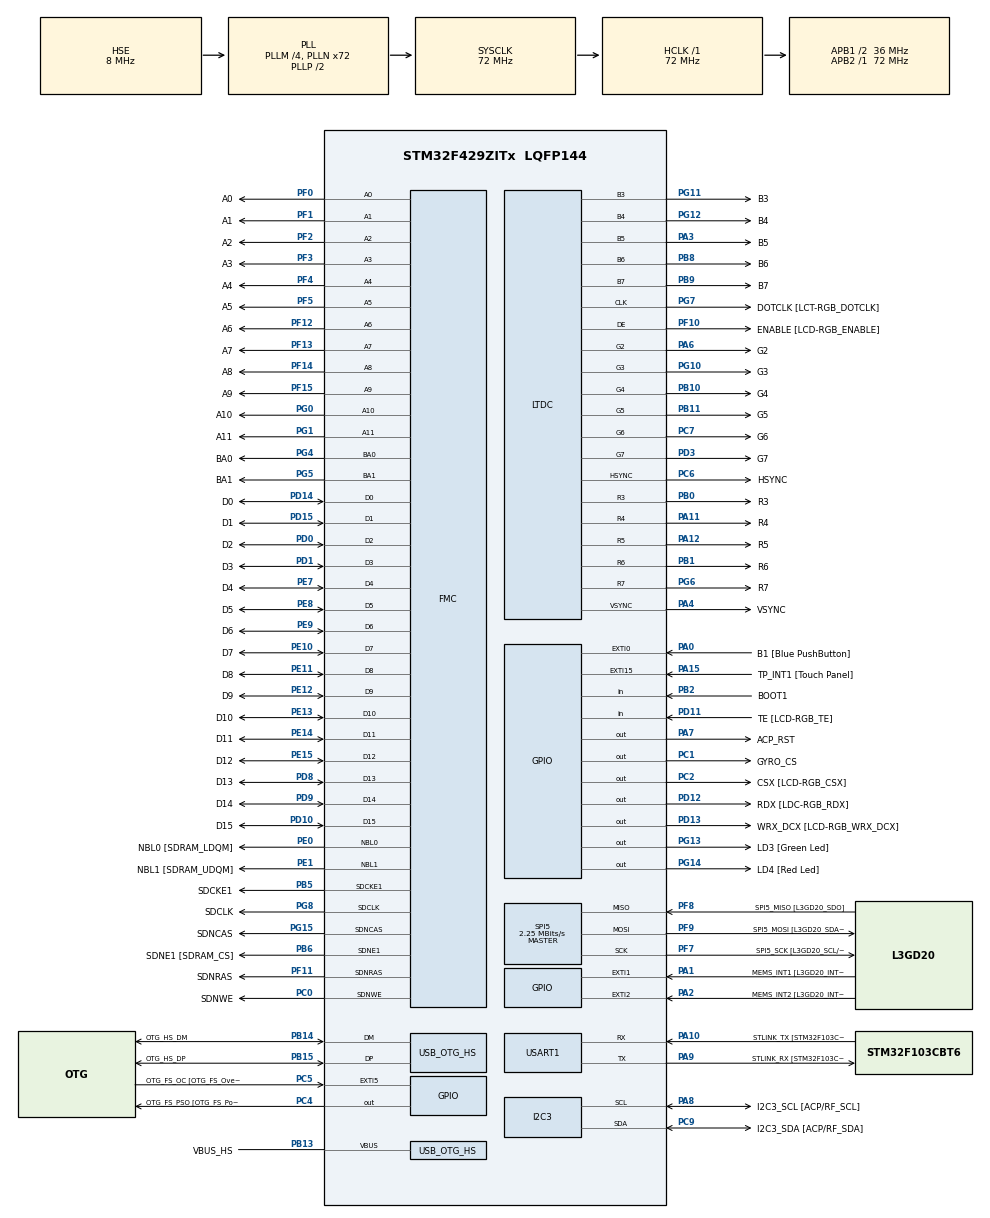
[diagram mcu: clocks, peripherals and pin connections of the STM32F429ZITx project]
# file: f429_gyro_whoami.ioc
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FMC.CASLatency1=FMC_SDRAM_CAS_LATENCY_3
FMC.ExitSelfRefreshDelay1=7
FMC.LoadToActiveDelay1=2
FMC.RCDDelay1=2
FMC.RPDelay1=2
FMC.RPDelay2=2
FMC.ReadBurst1=FMC_SDRAM_RBURST_DISABLE
FMC.ReadPipeDelay1=FMC_SDRAM_RPIPE_DELAY_1
FMC.ReadPipeDelay2=FMC_SDRAM_RPIPE_DELAY_1
FMC.RowCycleDelay1=7
FMC.RowCycleDelay2=7
FMC.SDClockPeriod1=FMC_SDRAM_CLOCK_PERIOD_2
FMC.SDClockPeriod2=FMC_SDRAM_CLOCK_PERIOD_2
FMC.SelfRefreshTime1=4
FMC.WriteRecoveryTime1=3
FREERTOS.Tasks01=defaultTask,0,4096,StartDefaultTask,Default,NULL,Dynamic,NULL,NULL
FREERTOS.configCHECK_FOR_STACK_OVERFLOW=2
FREERTOS.configTOTAL_HEAP_SIZE=32768
FREERTOS.configUSE_APPLICATION_TASK_TAG=1
FREERTOS.configUSE_COUNTING_SEMAPHORES=1
FREERTOS.configUSE_IDLE_HOOK=1
FREERTOS.configUSE_MALLOC_FAILED_HOOK=1
FREERTOS.configUSE_RECURSIVE_MUTEXES=1
LTDC.ActiveH=320
LTDC.ActiveW=240
LTDC.Alpha_L0=255
LTDC.BlendingFactor1_L0=LTDC_BLENDING_FACTOR1_PAxCA
LTDC.BlendingFactor2_L0=LTDC_BLENDING_FACTOR2_PAxCA
LTDC.FBStartAdress_L0=0xD0000000
LTDC.HBP=20
LTDC.HFP=10
LTDC.HSync=10
LTDC.ImageHeight_L0=320
LTDC.ImageWidth_L0=240
LTDC.Layers=0
LTDC.PixelFormat_L0=LTDC_PIXEL_FORMAT_RGB565
LTDC.VFP=4
LTDC.VSync=2
LTDC.WindowX1_L0=240
LTDC.WindowY1_L0=320
Mcu.Family=STM32F4
Mcu.Name=STM32F429ZITx
Mcu.Package=LQFP144
NVIC.DMA2D_IRQn=true\:5\:0\:true\:false\:true\:true\:true\:true\:true
NVIC.LTDC_IRQn=true\:5\:0\:true\:false\:true\:true\:true\:true\:true
NVIC.OTG_HS_IRQn=true\:5\:0\:false\:false\:true\:true\:true\:true\:true
NVIC.PriorityGroup=NVIC_PRIORITYGROUP_4
NVIC.TIM6_DAC_IRQn=true\:15\:0\:false\:false\:true\:false\:false\:true\:true
NVIC.TimeBase=TIM6_DAC_IRQn
NVIC.TimeBaseIP=TIM6
PA0/WKUP.GPIO_Label=B1 [Blue PushButton]
PA0/WKUP.GPIO_ModeDefaultEXTI=GPIO_MODE_EVT_RISING
PA0/WKUP.GPIO_PuPd=GPIO_NOPULL
PA0/WKUP.Signal=GPXTI0
PA1.GPIO_Label=MEMS_INT1 [L3GD20_INT1]
PA1.GPIO_ModeDefaultEXTI=GPIO_MODE_EVT_RISING
PA1.GPIO_PuPd=GPIO_NOPULL
PA1.Signal=GPXTI1
PA10.GPIO_Label=STLINK_TX [STM32F103CBT6_PA2]
PA10.Mode=Asynchronous
PA10.Signal=USART1_RX
PA11.GPIO_Label=R4
PA11.GPIO_Mode=GPIO_MODE_AF_PP
PA11.GPIO_PuPd=GPIO_NOPULL
PA11.GPIO_Speed=GPIO_SPEED_FREQ_LOW
PA11.Mode=RGB565
PA11.Signal=LTDC_R4
PA12.GPIO_Label=R5
PA12.GPIO_Mode=GPIO_MODE_AF_PP
PA12.GPIO_PuPd=GPIO_NOPULL
PA12.GPIO_Speed=GPIO_SPEED_FREQ_LOW
PA12.Mode=RGB565
PA12.Signal=LTDC_R5
PA13.GPIO_Label=SWDIO
PA13.Mode=Serial_Wire
PA13.Signal=SYS_JTMS-SWDIO
PA14.GPIO_Label=SWCLK
PA14.Mode=Serial_Wire
PA14.Signal=SYS_JTCK-SWCLK
PA15.GPIO_Label=TP_INT1 [Touch Panel]
PA15.GPIO_ModeDefaultEXTI=GPIO_MODE_EVT_RISING
PA15.GPIO_PuPd=GPIO_NOPULL
PA15.Signal=GPXTI15
PA2.GPIO_Label=MEMS_INT2 [L3GD20_INT2]
PA2.GPIO_ModeDefaultEXTI=GPIO_MODE_EVT_RISING
PA2.GPIO_PuPd=GPIO_NOPULL
PA2.Signal=GPXTI2
PA3.GPIO_Label=B5
PA3.GPIO_Mode=GPIO_MODE_AF_PP
PA3.GPIO_PuPd=GPIO_NOPULL
PA3.GPIO_Speed=GPIO_SPEED_FREQ_LOW
PA3.Mode=RGB565
PA3.Signal=LTDC_B5
PA4.GPIO_Label=VSYNC
PA4.GPIO_Mode=GPIO_MODE_AF_PP
PA4.GPIO_PuPd=GPIO_NOPULL
PA4.GPIO_Speed=GPIO_SPEED_FREQ_LOW
PA4.Mode=RGB565
PA4.Signal=LTDC_VSYNC
PA6.GPIO_Label=G2
PA6.GPIO_Mode=GPIO_MODE_AF_PP
PA6.GPIO_PuPd=GPIO_NOPULL
PA6.GPIO_Speed=GPIO_SPEED_FREQ_LOW
PA6.Mode=RGB565
PA6.Signal=LTDC_G2
PA7.GPIO_Label=ACP_RST
PA7.GPIO_Mode=GPIO_MODE_OUTPUT_PP
PA7.GPIO_PuPd=GPIO_NOPULL
PA7.GPIO_Speed=GPIO_SPEED_FREQ_LOW
PA7.Signal=GPIO_Output
PA8.GPIO_Label=I2C3_SCL [ACP/RF_SCL]
PA8.GPIO_Mode=GPIO_MODE_AF_OD
PA8.GPIO_Pu=GPIO_PULLUP
PA8.GPIO_PuPd=GPIO_NOPULL
PA8.GPIO_Speed=GPIO_SPEED_FREQ_LOW
PA8.Mode=I2C
PA8.Signal=I2C3_SCL
PA9.GPIO_Label=STLINK_RX [STM32F103CBT6_PA3]
PA9.Mode=Asynchronous
PA9.Signal=USART1_TX
PB0.GPIO_Label=R3
PB0.GPIO_Mode=GPIO_MODE_AF_PP
PB0.GPIO_PuPd=GPIO_NOPULL
PB0.GPIO_Speed=GPIO_SPEED_FREQ_LOW
PB0.Mode=RGB565
PB0.Signal=LTDC_R3
PB1.GPIO_Label=R6
PB1.GPIO_Mode=GPIO_MODE_AF_PP
PB1.GPIO_PuPd=GPIO_NOPULL
PB1.GPIO_Speed=GPIO_SPEED_FREQ_LOW
PB1.Mode=RGB565
PB1.Signal=LTDC_R6
PB10.GPIO_Label=G4
PB10.GPIO_Mode=GPIO_MODE_AF_PP
PB10.GPIO_PuPd=GPIO_NOPULL
PB10.GPIO_Speed=GPIO_SPEED_FREQ_LOW
PB10.Mode=RGB565
PB10.Signal=LTDC_G4
PB11.GPIO_Label=G5
PB11.GPIO_Mode=GPIO_MODE_AF_PP
PB11.GPIO_PuPd=GPIO_NOPULL
PB11.GPIO_Speed=GPIO_SPEED_FREQ_LOW
PB11.Mode=RGB565
PB11.Signal=LTDC_G5
PB12.GPIO_Label=OTG_HS_ID
PB12.GPIO_Mode=GPIO_MODE_AF_PP
PB12.GPIO_PuPd=GPIO_NOPULL
PB12.GPIO_Speed=GPIO_SPEED_FREQ_LOW
PB12.Signal=USB_OTG_HS_ID
PB13.GPIO_Label=VBUS_HS
PB13.GPIO_Mode=GPIO_MODE_INPUT
PB13.GPIO_PuPd=GPIO_NOPULL
PB13.Mode=Activate_VBUS_FS
PB13.Signal=USB_OTG_HS_VBUS
PB14.GPIO_Label=OTG_HS_DM
PB14.GPIO_Mode=GPIO_MODE_AF_PP
PB14.GPIO_PuPd=GPIO_NOPULL
PB14.GPIO_Speed=GPIO_SPEED_FREQ_LOW
PB14.Mode=Host_FS
PB14.Signal=USB_OTG_HS_DM
PB15.GPIO_Label=OTG_HS_DP
PB15.GPIO_Mode=GPIO_MODE_AF_PP
PB15.GPIO_PuPd=GPIO_NOPULL
PB15.GPIO_Speed=GPIO_SPEED_FREQ_LOW
PB15.Mode=Host_FS
PB15.Signal=USB_OTG_HS_DP
PB2/BOOT1.GPIO_Label=BOOT1
PB2/BOOT1.GPIO_Mode=GPIO_MODE_INPUT
PB2/BOOT1.GPIO_PuPd=GPIO_NOPULL
PB2/BOOT1.Signal=GPIO_Input
PB5.GPIO_Label=SDCKE1
PB5.GPIO_Mode=GPIO_MODE_AF_PP
PB5.GPIO_PuPd=GPIO_NOPULL
PB5.GPIO_Speed=GPIO_SPEED_FREQ_VERY_HIGH
PB5.Mode=SdramChipSelect2_1
PB5.Signal=FMC_SDCKE1
PB6.GPIO_Label=SDNE1 [SDRAM_CS]
PB6.GPIO_Mode=GPIO_MODE_AF_PP
PB6.GPIO_PuPd=GPIO_NOPULL
PB6.GPIO_Speed=GPIO_SPEED_FREQ_VERY_HIGH
PB6.Mode=SdramChipSelect2_1
PB6.Signal=FMC_SDNE1
PB8.GPIO_Label=B6
PB8.GPIO_Mode=GPIO_MODE_AF_PP
PB8.GPIO_PuPd=GPIO_NOPULL
PB8.GPIO_Speed=GPIO_SPEED_FREQ_LOW
PB8.Mode=RGB565
PB8.Signal=LTDC_B6
PB9.GPIO_Label=B7
PB9.GPIO_Mode=GPIO_MODE_AF_PP
PB9.GPIO_PuPd=GPIO_NOPULL
PB9.GPIO_Speed=GPIO_SPEED_FREQ_LOW
PB9.Mode=RGB565
PB9.Signal=LTDC_B7
PC0.GPIO_Label=SDNWE
PC0.GPIO_Mode=GPIO_MODE_AF_PP
PC0.GPIO_PuPd=GPIO_NOPULL
PC0.GPIO_Speed=GPIO_SPEED_FREQ_VERY_HIGH
PC0.Signal=FMC_SDNWE
PC1.GPIO_Label=GYRO_CS
PC1.GPIO_Mode=GPIO_MODE_OUTPUT_PP
PC1.GPIO_PuPd=GPIO_NOPULL
PC1.GPIO_Speed=GPIO_SPEED_FREQ_LOW
PC1.PinState=GPIO_PIN_SET
PC1.Signal=GPIO_Output
PC10.GPIO_Label=R2
PC10.GPIO_Mode=GPIO_MODE_AF_PP
PC10.GPIO_PuPd=GPIO_NOPULL
PC10.GPIO_Speed=GPIO_SPEED_FREQ_LOW
PC10.Signal=LTDC_R2
PC14/OSC32_IN.GPIO_Label=PC14-OSC32_IN
PC14/OSC32_IN.Signal=RCC_OSC32_IN
PC15/OSC32_OUT.GPIO_Label=PC15-OSC32_OUT
PC15/OSC32_OUT.Signal=RCC_OSC32_OUT
PC2.GPIO_Label=CSX [LCD-RGB_CSX]
PC2.GPIO_Mode=GPIO_MODE_OUTPUT_PP
PC2.GPIO_PuPd=GPIO_NOPULL
PC2.GPIO_Speed=GPIO_SPEED_FREQ_LOW
PC2.Signal=GPIO_Output
PC4.GPIO_Label=OTG_FS_PSO [OTG_FS_PowerSwitchOn]
PC4.GPIO_Mode=GPIO_MODE_OUTPUT_PP
PC4.GPIO_PuPd=GPIO_NOPULL
PC4.GPIO_Speed=GPIO_SPEED_FREQ_LOW
PC4.Signal=GPIO_Output
PC5.GPIO_Label=OTG_FS_OC [OTG_FS_OverCurrent]
PC5.GPIO_ModeDefaultEXTI=GPIO_MODE_EVT_RISING
PC5.Signal=GPXTI5
PC6.GPIO_Label=HSYNC
PC6.GPIO_Mode=GPIO_MODE_AF_PP
PC6.GPIO_PuPd=GPIO_NOPULL
PC6.GPIO_Speed=GPIO_SPEED_FREQ_LOW
PC6.Mode=RGB565
PC6.Signal=LTDC_HSYNC
PC7.GPIO_Label=G6
PC7.GPIO_Mode=GPIO_MODE_AF_PP
PC7.GPIO_PuPd=GPIO_NOPULL
PC7.GPIO_Speed=GPIO_SPEED_FREQ_LOW
PC7.Mode=RGB565
PC7.Signal=LTDC_G6
PC9.GPIO_Label=I2C3_SDA [ACP/RF_SDA]
PC9.GPIO_Mode=GPIO_MODE_AF_OD
PC9.GPIO_Pu=GPIO_PULLUP
PC9.GPIO_PuPd=GPIO_NOPULL
PC9.GPIO_Speed=GPIO_SPEED_FREQ_LOW
PC9.Mode=I2C
PC9.Signal=I2C3_SDA
PD0.GPIO_Label=D2
PD0.GPIO_Mode=GPIO_MODE_AF_PP
PD0.GPIO_PuPd=GPIO_NOPULL
PD0.GPIO_Speed=GPIO_SPEED_FREQ_VERY_HIGH
PD0.Signal=FMC_D2_DA2
PD1.GPIO_Label=D3
PD1.GPIO_Mode=GPIO_MODE_AF_PP
PD1.GPIO_PuPd=GPIO_NOPULL
PD1.GPIO_Speed=GPIO_SPEED_FREQ_VERY_HIGH
PD1.Signal=FMC_D3_DA3
PD10.GPIO_Label=D15
PD10.GPIO_Mode=GPIO_MODE_AF_PP
PD10.GPIO_PuPd=GPIO_NOPULL
PD10.GPIO_Speed=GPIO_SPEED_FREQ_VERY_HIGH
PD10.Signal=FMC_D15_DA15
PD11.GPIO_Label=TE [LCD-RGB_TE]
PD11.GPIO_Mode=GPIO_MODE_INPUT
PD11.GPIO_PuPd=GPIO_NOPULL
PD11.Signal=GPIO_Input
PD12.GPIO_Label=RDX [LDC-RGB_RDX]
PD12.GPIO_Mode=GPIO_MODE_OUTPUT_PP
PD12.GPIO_PuPd=GPIO_NOPULL
PD12.GPIO_Speed=GPIO_SPEED_FREQ_LOW
PD12.Signal=GPIO_Output
PD13.GPIO_Label=WRX_DCX [LCD-RGB_WRX_DCX]
PD13.GPIO_Mode=GPIO_MODE_OUTPUT_PP
PD13.GPIO_PuPd=GPIO_NOPULL
PD13.GPIO_Speed=GPIO_SPEED_FREQ_LOW
PD13.Signal=GPIO_Output
PD14.GPIO_Label=D0
PD14.GPIO_Mode=GPIO_MODE_AF_PP
PD14.GPIO_PuPd=GPIO_NOPULL
PD14.GPIO_Speed=GPIO_SPEED_FREQ_VERY_HIGH
PD14.Signal=FMC_D0_DA0
PD15.GPIO_Label=D1
PD15.GPIO_Mode=GPIO_MODE_AF_PP
PD15.GPIO_PuPd=GPIO_NOPULL
PD15.GPIO_Speed=GPIO_SPEED_FREQ_VERY_HIGH
PD15.Signal=FMC_D1_DA1
PD3.GPIO_Label=G7
PD3.GPIO_Mode=GPIO_MODE_AF_PP
PD3.GPIO_PuPd=GPIO_NOPULL
PD3.GPIO_Speed=GPIO_SPEED_FREQ_LOW
PD3.Mode=RGB565
PD3.Signal=LTDC_G7
PD6.GPIO_Label=B2
PD6.GPIO_Mode=GPIO_MODE_AF_PP
PD6.GPIO_PuPd=GPIO_NOPULL
PD6.GPIO_Speed=GPIO_SPEED_FREQ_LOW
PD6.Signal=LTDC_B2
PD8.GPIO_Label=D13
PD8.GPIO_Mode=GPIO_MODE_AF_PP
PD8.GPIO_PuPd=GPIO_NOPULL
PD8.GPIO_Speed=GPIO_SPEED_FREQ_VERY_HIGH
PD8.Signal=FMC_D13_DA13
PD9.GPIO_Label=D14
PD9.GPIO_Mode=GPIO_MODE_AF_PP
PD9.GPIO_PuPd=GPIO_NOPULL
PD9.GPIO_Speed=GPIO_SPEED_FREQ_VERY_HIGH
PD9.Signal=FMC_D14_DA14
PE0.GPIO_Label=NBL0 [SDRAM_LDQM]
PE0.GPIO_Mode=GPIO_MODE_AF_PP
PE0.GPIO_PuPd=GPIO_NOPULL
PE0.GPIO_Speed=GPIO_SPEED_FREQ_VERY_HIGH
PE0.Signal=FMC_NBL0
PE1.GPIO_Label=NBL1 [SDRAM_UDQM]
PE1.GPIO_Mode=GPIO_MODE_AF_PP
PE1.GPIO_PuPd=GPIO_NOPULL
PE1.GPIO_Speed=GPIO_SPEED_FREQ_VERY_HIGH
PE1.Signal=FMC_NBL1
PE10.GPIO_Label=D7
PE10.GPIO_Mode=GPIO_MODE_AF_PP
PE10.GPIO_PuPd=GPIO_NOPULL
PE10.GPIO_Speed=GPIO_SPEED_FREQ_VERY_HIGH
PE10.Signal=FMC_D7_DA7
PE11.GPIO_Label=D8
PE11.GPIO_Mode=GPIO_MODE_AF_PP
PE11.GPIO_PuPd=GPIO_NOPULL
PE11.GPIO_Speed=GPIO_SPEED_FREQ_VERY_HIGH
PE11.Signal=FMC_D8_DA8
PE12.GPIO_Label=D9
PE12.GPIO_Mode=GPIO_MODE_AF_PP
PE12.GPIO_PuPd=GPIO_NOPULL
PE12.GPIO_Speed=GPIO_SPEED_FREQ_VERY_HIGH
PE12.Signal=FMC_D9_DA9
PE13.GPIO_Label=D10
PE13.GPIO_Mode=GPIO_MODE_AF_PP
PE13.GPIO_PuPd=GPIO_NOPULL
PE13.GPIO_Speed=GPIO_SPEED_FREQ_VERY_HIGH
PE13.Signal=FMC_D10_DA10
PE14.GPIO_Label=D11
PE14.GPIO_Mode=GPIO_MODE_AF_PP
PE14.GPIO_PuPd=GPIO_NOPULL
PE14.GPIO_Speed=GPIO_SPEED_FREQ_VERY_HIGH
PE14.Signal=FMC_D11_DA11
PE15.GPIO_Label=D12
PE15.GPIO_Mode=GPIO_MODE_AF_PP
PE15.GPIO_PuPd=GPIO_NOPULL
PE15.GPIO_Speed=GPIO_SPEED_FREQ_VERY_HIGH
PE15.Signal=FMC_D12_DA12
PE7.GPIO_Label=D4
PE7.GPIO_Mode=GPIO_MODE_AF_PP
PE7.GPIO_PuPd=GPIO_NOPULL
PE7.GPIO_Speed=GPIO_SPEED_FREQ_VERY_HIGH
PE7.Signal=FMC_D4_DA4
PE8.GPIO_Label=D5
PE8.GPIO_Mode=GPIO_MODE_AF_PP
PE8.GPIO_PuPd=GPIO_NOPULL
PE8.GPIO_Speed=GPIO_SPEED_FREQ_VERY_HIGH
PE8.Signal=FMC_D5_DA5
PE9.GPIO_Label=D6
PE9.GPIO_Mode=GPIO_MODE_AF_PP
PE9.GPIO_PuPd=GPIO_NOPULL
PE9.GPIO_Speed=GPIO_SPEED_FREQ_VERY_HIGH
PE9.Signal=FMC_D6_DA6
PF0.GPIO_Label=A0
PF0.GPIO_Mode=GPIO_MODE_AF_PP
PF0.GPIO_PuPd=GPIO_NOPULL
PF0.GPIO_Speed=GPIO_SPEED_FREQ_VERY_HIGH
PF0.Signal=FMC_A0
PF1.GPIO_Label=A1
PF1.GPIO_Mode=GPIO_MODE_AF_PP
PF1.GPIO_PuPd=GPIO_NOPULL
PF1.GPIO_Speed=GPIO_SPEED_FREQ_VERY_HIGH
PF1.Signal=FMC_A1
PF10.GPIO_Label=ENABLE [LCD-RGB_ENABLE]
PF10.GPIO_Mode=GPIO_MODE_AF_PP
PF10.GPIO_PuPd=GPIO_NOPULL
PF10.GPIO_Speed=GPIO_SPEED_FREQ_LOW
PF10.Mode=RGB565
PF10.Signal=LTDC_DE
PF11.GPIO_Label=SDNRAS
PF11.GPIO_Mode=GPIO_MODE_AF_PP
PF11.GPIO_PuPd=GPIO_NOPULL
PF11.GPIO_Speed=GPIO_SPEED_FREQ_VERY_HIGH
PF11.Signal=FMC_SDNRAS
PF12.GPIO_Label=A6
PF12.GPIO_Mode=GPIO_MODE_AF_PP
PF12.GPIO_PuPd=GPIO_NOPULL
PF12.GPIO_Speed=GPIO_SPEED_FREQ_VERY_HIGH
PF12.Signal=FMC_A6
PF13.GPIO_Label=A7
PF13.GPIO_Mode=GPIO_MODE_AF_PP
PF13.GPIO_PuPd=GPIO_NOPULL
PF13.GPIO_Speed=GPIO_SPEED_FREQ_VERY_HIGH
PF13.Signal=FMC_A7
PF14.GPIO_Label=A8
PF14.GPIO_Mode=GPIO_MODE_AF_PP
PF14.GPIO_PuPd=GPIO_NOPULL
PF14.GPIO_Speed=GPIO_SPEED_FREQ_VERY_HIGH
PF14.Signal=FMC_A8
PF15.GPIO_Label=A9
PF15.GPIO_Mode=GPIO_MODE_AF_PP
PF15.GPIO_PuPd=GPIO_NOPULL
PF15.GPIO_Speed=GPIO_SPEED_FREQ_VERY_HIGH
PF15.Signal=FMC_A9
PF2.GPIO_Label=A2
PF2.GPIO_Mode=GPIO_MODE_AF_PP
PF2.GPIO_PuPd=GPIO_NOPULL
PF2.GPIO_Speed=GPIO_SPEED_FREQ_VERY_HIGH
PF2.Signal=FMC_A2
PF3.GPIO_Label=A3
PF3.GPIO_Mode=GPIO_MODE_AF_PP
PF3.GPIO_PuPd=GPIO_NOPULL
PF3.GPIO_Speed=GPIO_SPEED_FREQ_VERY_HIGH
PF3.Signal=FMC_A3
PF4.GPIO_Label=A4
PF4.GPIO_Mode=GPIO_MODE_AF_PP
PF4.GPIO_PuPd=GPIO_NOPULL
PF4.GPIO_Speed=GPIO_SPEED_FREQ_VERY_HIGH
PF4.Signal=FMC_A4
PF5.GPIO_Label=A5
PF5.GPIO_Mode=GPIO_MODE_AF_PP
PF5.GPIO_PuPd=GPIO_NOPULL
PF5.GPIO_Speed=GPIO_SPEED_FREQ_VERY_HIGH
PF5.Signal=FMC_A5
PF7.GPIO_Label=SPI5_SCK [L3GD20_SCL/SPC]
PF7.GPIO_Mode=GPIO_MODE_AF_PP
PF7.GPIO_PuPd=GPIO_NOPULL
PF7.GPIO_Speed=GPIO_SPEED_FREQ_LOW
PF7.Mode=Full_Duplex_Master
PF7.Signal=SPI5_SCK
PF8.GPIO_Label=SPI5_MISO [L3GD20_SDO]
PF8.GPIO_Mode=GPIO_MODE_AF_PP
PF8.GPIO_PuPd=GPIO_NOPULL
PF8.GPIO_Speed=GPIO_SPEED_FREQ_LOW
PF8.Mode=Full_Duplex_Master
PF8.Signal=SPI5_MISO
PF9.GPIO_Label=SPI5_MOSI [L3GD20_SDA/SDI/SDO]
PF9.GPIO_Mode=GPIO_MODE_AF_PP
PF9.GPIO_PuPd=GPIO_NOPULL
PF9.GPIO_Speed=GPIO_SPEED_FREQ_LOW
PF9.Mode=Full_Duplex_Master
PF9.Signal=SPI5_MOSI
PG0.GPIO_Label=A10
PG0.GPIO_Mode=GPIO_MODE_AF_PP
PG0.GPIO_PuPd=GPIO_NOPULL
PG0.GPIO_Speed=GPIO_SPEED_FREQ_VERY_HIGH
PG0.Signal=FMC_A10
PG1.GPIO_Label=A11
PG1.GPIO_Mode=GPIO_MODE_AF_PP
PG1.GPIO_PuPd=GPIO_NOPULL
PG1.GPIO_Speed=GPIO_SPEED_FREQ_VERY_HIGH
PG1.Signal=FMC_A11
PG10.GPIO_Label=G3
PG10.GPIO_Mode=GPIO_MODE_AF_PP
PG10.GPIO_PuPd=GPIO_NOPULL
PG10.GPIO_Speed=GPIO_SPEED_FREQ_LOW
PG10.Mode=RGB565
PG10.Signal=LTDC_G3
PG11.GPIO_Label=B3
PG11.GPIO_Mode=GPIO_MODE_AF_PP
PG11.GPIO_PuPd=GPIO_NOPULL
PG11.GPIO_Speed=GPIO_SPEED_FREQ_LOW
PG11.Mode=RGB565
PG11.Signal=LTDC_B3
PG12.GPIO_Label=B4
PG12.GPIO_Mode=GPIO_MODE_AF_PP
PG12.GPIO_PuPd=GPIO_NOPULL
PG12.GPIO_Speed=GPIO_SPEED_FREQ_LOW
PG12.Mode=RGB565
PG12.Signal=LTDC_B4
PG13.GPIO_Label=LD3 [Green Led]
PG13.GPIO_Mode=GPIO_MODE_OUTPUT_PP
PG13.GPIO_PuPd=GPIO_NOPULL
PG13.GPIO_Speed=GPIO_SPEED_FREQ_LOW
PG13.Signal=GPIO_Output
PG14.GPIO_Label=LD4 [Red Led]
PG14.GPIO_Mode=GPIO_MODE_OUTPUT_PP
PG14.GPIO_PuPd=GPIO_NOPULL
PG14.GPIO_Speed=GPIO_SPEED_FREQ_LOW
PG14.Signal=GPIO_Output
PG15.GPIO_Label=SDNCAS
PG15.GPIO_Mode=GPIO_MODE_AF_PP
PG15.GPIO_PuPd=GPIO_NOPULL
PG15.GPIO_Speed=GPIO_SPEED_FREQ_VERY_HIGH
PG15.Signal=FMC_SDNCAS
PG4.GPIO_Label=BA0
PG4.GPIO_Mode=GPIO_MODE_AF_PP
PG4.GPIO_PuPd=GPIO_NOPULL
PG4.GPIO_Speed=GPIO_SPEED_FREQ_VERY_HIGH
PG4.Signal=FMC_A14_BA0
PG5.GPIO_Label=BA1
PG5.GPIO_Mode=GPIO_MODE_AF_PP
PG5.GPIO_PuPd=GPIO_NOPULL
PG5.GPIO_Speed=GPIO_SPEED_FREQ_VERY_HIGH
PG5.Signal=FMC_A15_BA1
PG6.GPIO_Label=R7
PG6.GPIO_Mode=GPIO_MODE_AF_PP
PG6.GPIO_PuPd=GPIO_NOPULL
PG6.GPIO_Speed=GPIO_SPEED_FREQ_LOW
PG6.Mode=RGB565
PG6.Signal=LTDC_R7
PG7.GPIO_Label=DOTCLK [LCT-RGB_DOTCLK]
PG7.GPIO_Mode=GPIO_MODE_AF_PP
PG7.GPIO_PuPd=GPIO_NOPULL
PG7.GPIO_Speed=GPIO_SPEED_FREQ_LOW
PG7.Mode=RGB565
PG7.Signal=LTDC_CLK
PG8.GPIO_Label=SDCLK
PG8.GPIO_Mode=GPIO_MODE_AF_PP
PG8.GPIO_PuPd=GPIO_NOPULL
PG8.GPIO_Speed=GPIO_SPEED_FREQ_VERY_HIGH
PG8.Signal=FMC_SDCLK
PH0/OSC_IN.GPIO_Label=PH0-OSC_IN
PH0/OSC_IN.Mode=HSE-External-Oscillator
PH0/OSC_IN.Signal=RCC_OSC_IN
PH1/OSC_OUT.GPIO_Label=PH1-OSC_OUT
PH1/OSC_OUT.Mode=HSE-External-Oscillator
PH1/OSC_OUT.Signal=RCC_OSC_OUT
ProjectManager.HeapSize=0x200
ProjectManager.StackSize=0x400
ProjectManager.TargetToolchain=STM32CubeIDE
RCC.48MHZClocksFreq_Value=48000000
RCC.AHBFreq_Value=72000000
RCC.APB1CLKDivider=RCC_HCLK_DIV2
RCC.APB1Freq_Value=36000000
RCC.APB1TimFreq_Value=72000000
RCC.APB2Freq_Value=72000000
RCC.APB2TimFreq_Value=72000000
RCC.CortexFreq_Value=72000000
RCC.HCLKFreq_Value=72000000
RCC.HSE_VALUE=8000000
RCC.HSI_VALUE=16000000
RCC.LSE_VALUE=32768
RCC.PLLM=4
RCC.PLLN=72
RCC.PLLQ=3
RCC.PLLSAIN=50
RCC.SYSCLKFreq_VALUE=72000000
RCC.SYSCLKSource=RCC_SYSCLKSOURCE_PLLCLK
RCC.VCOOutputFreq_Value=144000000
SH.FMC_A0.0=FMC_A0,12b-sda1
SH.FMC_A1.0=FMC_A1,12b-sda1
SH.FMC_A10.0=FMC_A10,12b-sda1
SH.FMC_A11.0=FMC_A11,12b-sda1
SH.FMC_A14_BA0.0=FMC_BA0,FourSdramBanks1
SH.FMC_A15_BA1.0=FMC_BA1,FourSdramBanks1
SH.FMC_A2.0=FMC_A2,12b-sda1
SH.FMC_A3.0=FMC_A3,12b-sda1
SH.FMC_A4.0=FMC_A4,12b-sda1
SH.FMC_A5.0=FMC_A5,12b-sda1
SH.FMC_A6.0=FMC_A6,12b-sda1
SH.FMC_A7.0=FMC_A7,12b-sda1
SH.FMC_A8.0=FMC_A8,12b-sda1
SH.FMC_A9.0=FMC_A9,12b-sda1
SH.FMC_D0_DA0.0=FMC_D0,sd-16b-d1
SH.FMC_D10_DA10.0=FMC_D10,sd-16b-d1
SH.FMC_D11_DA11.0=FMC_D11,sd-16b-d1
SH.FMC_D12_DA12.0=FMC_D12,sd-16b-d1
SH.FMC_D13_DA13.0=FMC_D13,sd-16b-d1
SH.FMC_D14_DA14.0=FMC_D14,sd-16b-d1
SH.FMC_D15_DA15.0=FMC_D15,sd-16b-d1
SH.FMC_D1_DA1.0=FMC_D1,sd-16b-d1
SH.FMC_D2_DA2.0=FMC_D2,sd-16b-d1
SH.FMC_D3_DA3.0=FMC_D3,sd-16b-d1
SH.FMC_D4_DA4.0=FMC_D4,sd-16b-d1
SH.FMC_D5_DA5.0=FMC_D5,sd-16b-d1
SH.FMC_D6_DA6.0=FMC_D6,sd-16b-d1
SH.FMC_D7_DA7.0=FMC_D7,sd-16b-d1
SH.FMC_D8_DA8.0=FMC_D8,sd-16b-d1
SH.FMC_D9_DA9.0=FMC_D9,sd-16b-d1
SH.FMC_NBL0.0=FMC_NBL0,Sd2ByteEnable1
SH.FMC_NBL1.0=FMC_NBL1,Sd2ByteEnable1
SH.FMC_SDCLK.0=FMC_SDCLK,12b-sda1
SH.FMC_SDNCAS.0=FMC_SDNCAS,12b-sda1
SH.FMC_SDNRAS.0=FMC_SDNRAS,12b-sda1
SH.FMC_SDNWE.0=FMC_SDNWE,12b-sda1
SPI5.BaudRatePrescaler=SPI_BAUDRATEPRESCALER_32
SPI5.CLKPhase=SPI_PHASE_2EDGE
SPI5.CLKPolarity=SPI_POLARITY_HIGH
SPI5.CalculateBaudRate=2.25 MBits/s
SPI5.Direction=SPI_DIRECTION_2LINES
SPI5.Mode=SPI_MODE_MASTER
SPI5.VirtualType=VM_MASTER
USART1.VirtualMode=VM_ASYNC
USB_HOST.BSP.number=1
USB_HOST.USBH_HandleTypeDef-CDC_HS=hUsbHostHS
USB_HOST.VirtualModeHS=Cdc
USB_HOST0.BSP.STBoard=false
USB_HOST0.BSP.api=UnknownBspDriver
USB_HOST0.BSP.instance=PC4
USB_HOST0.BSP.ip=GPIO
USB_HOST0.BSP.mode=Output
USB_HOST0.BSP.name=Drive_VBUS_HS
USB_HOST0.BSP.solution=PC4
USB_OTG_HS.VirtualMode-Host_FS=Host_FS
VP_CRC_VS_CRC.Mode=CRC_Activate
VP_DMA2D_VS_DMA2D.Mode=DMA2D_Activate
VP_FREERTOS_VS_CMSIS_V1.Mode=CMSIS_V1
VP_SYS_VS_tim6.Mode=TIM6
VP_TIM1_VS_ClockSourceINT.Mode=Internal
VP_USB_HOST_VS_USB_HOST_CDC_HS.Mode=CDC_HS
board=STM32F429I-DISC1

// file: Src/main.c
/* USER CODE BEGIN Header */
/**
  ******************************************************************************
  * @file           : main.c
  * @brief          : Main program body
  ******************************************************************************
  * @attention
  *
  * Copyright (c) 2026 STMicroelectronics.
  * All rights reserved.
  *
  * This software is licensed under terms that can be found in the LICENSE file
  * in the root directory of this software component.
  * If no LICENSE file comes with this software, it is provided AS-IS.
  *
  ******************************************************************************
  */
/* USER CODE END Header */

#include "main.h"
#include "cmsis_os.h"
#include "crc.h"
#include "dma2d.h"
#include "i2c.h"
#include "ltdc.h"
#include "spi.h"
#include "tim.h"
#include "usart.h"
#include "usb_host.h"
#include "gpio.h"
#include "fmc.h"

/* USER CODE BEGIN Includes */
#include "i3g4250d_reg.h"
#include "i3g4250d_platform.h"
#include <stdio.h>
#include <string.h>
/* USER CODE END Includes */

/* USER CODE BEGIN PTD */

/**
 * @brief Gyroscope error codes (production-ready error handling)
 */
typedef enum {
  GYRO_OK                    =  0,   /**< Success */
  GYRO_ERR_SPI_COMM          = -1,   /**< SPI communication error */
  GYRO_ERR_WRONG_DEVICE      = -2,   /**< WHO_AM_I mismatch */
  GYRO_ERR_POWER_MODE        = -3,   /**< Power mode set failed */
  GYRO_ERR_AXIS_X_CONFIG     = -4,   /**< X-axis enable failed */
  GYRO_ERR_AXIS_Y_CONFIG     = -5,   /**< Y-axis enable failed */
  GYRO_ERR_AXIS_Z_CONFIG     = -6,   /**< Z-axis enable failed */
  GYRO_ERR_ODR_CONFIG        = -7,   /**< Output data rate config failed */
  GYRO_ERR_FULLSCALE_CONFIG  = -8,   /**< Full-scale config failed */
  GYRO_ERR_TEMP_READ         = -9,   /**< Temperature read failed */
  GYRO_ERR_SELFTEST_FAIL     = -10,  /**< Self-test failed */
  GYRO_ERR_DATA_READ         = -11,  /**< Angular rate read failed */
  GYRO_ERR_TIMEOUT           = -12,  /**< Operation timeout */
} gyro_error_t;

/* USER CODE END PTD */

/* USER CODE BEGIN PD */
// LED pins (STM32F429-DISCO)
#define LED_GREEN_PORT GPIOG
#define LED_GREEN_PIN  GPIO_PIN_13
#define LED_RED_PORT   GPIOG
#define LED_RED_PIN    GPIO_PIN_14
// Self-test limits for ±245 dps: 130 dps ± %20 tolerance
#define SELF_TEST_MIN_LSB 10400  // ~91 dps (130 - 30%)
#define SELF_TEST_MAX_LSB 18600  // ~163 dps (130 + 30%)

// UART handle (external)
extern UART_HandleTypeDef huart1;

/* USER CODE END PD */

/* USER CODE BEGIN PV */

// Gyroscope context
static stmdev_ctx_t gyro_ctx;
// Test değişkenleri
static uint8_t whoami_id = 0;
static int16_t gyro_data[3] = {0};   // X, Y, Z (raw değerler)
static uint8_t temp_raw = 0;         // Ham sicaklik değeri
static float temp_celsius = 0.0f;    // Sicaklik (°C)
/* USER CODE END PV */

void SystemClock_Config(void);
void MX_FREERTOS_Init(void);

/* USER CODE BEGIN 0 */

/**
 * @brief  Turn on LED
 * @param  led_id: 0=Green, 1=Red
 */
void i3g4250d_platform_led_on(uint8_t led_id)
{
  if (led_id == PROPERTY_DISABLE) {
    HAL_GPIO_WritePin(LED_GREEN_PORT, LED_GREEN_PIN, GPIO_PIN_SET);
  } else if (led_id == PROPERTY_ENABLE) {
    HAL_GPIO_WritePin(LED_RED_PORT, LED_RED_PIN, GPIO_PIN_SET);
  }
}

/**
 * @brief  Turn off LED
 * @param  led_id: 0=Green, 1=Red
 */
void i3g4250d_platform_led_off(uint8_t led_id)
{
  if (led_id == PROPERTY_DISABLE) {
    HAL_GPIO_WritePin(LED_GREEN_PORT, LED_GREEN_PIN, GPIO_PIN_RESET);
  } else if (led_id == PROPERTY_ENABLE) {
    HAL_GPIO_WritePin(LED_RED_PORT, LED_RED_PIN, GPIO_PIN_RESET);
  }
}

/**
 * @brief  Print message via UART
 * @param  msg: Null-terminated string
 */
void i3g4250d_platform_print(const char *msg)
{
  HAL_UART_Transmit(&huart1, (uint8_t*)msg, strlen(msg), 100);
}

/**
  * @brief  Initialize gyroscope
  * @retval gyro_error_t: GYRO_OK on success, error code on failure
  */
static gyro_error_t gyro_init(void)
{
  int32_t ret;

  // 1. WHO_AM_I kontrolü
  ret = i3g4250d_device_id_get(&gyro_ctx, &whoami_id);
  if (ret != 0) {
    return GYRO_ERR_SPI_COMM;
  }

  if (whoami_id != I3G4250D_ID) {
    return GYRO_ERR_WRONG_DEVICE;
  }

  // 2. Power-on mode (PD bit = 1)
  ret = i3g4250d_power_mode_set(&gyro_ctx, PROPERTY_ENABLE);
  if (ret != 0) {
    return GYRO_ERR_POWER_MODE;
  }

  // 3. Enable all axes (X, Y, Z)
  ret = i3g4250d_axis_x_data_set(&gyro_ctx, PROPERTY_ENABLE);
  if (ret != 0) { return GYRO_ERR_AXIS_X_CONFIG; }

  ret = i3g4250d_axis_y_data_set(&gyro_ctx, PROPERTY_ENABLE);
  if (ret != 0) { return GYRO_ERR_AXIS_Y_CONFIG; }

  ret = i3g4250d_axis_z_data_set(&gyro_ctx, PROPERTY_ENABLE);
  if (ret != 0) { return GYRO_ERR_AXIS_Z_CONFIG; }

  // 4. Output data rate: 100 Hz
  ret = i3g4250d_data_rate_set(&gyro_ctx, I3G4250D_ODR_100Hz);
  if (ret != 0) {
    return GYRO_ERR_ODR_CONFIG;
  }

  // 5. Full-scale: ±245 dps
  ret = i3g4250d_full_scale_set(&gyro_ctx, I3G4250D_245dps);
  if (ret != 0) {
    return GYRO_ERR_FULLSCALE_CONFIG;
  }

  // 6. Test: Sicaklik oku (opsiyonel)
  ret = i3g4250d_temperature_raw_get(&gyro_ctx, &temp_raw);
  if (ret != 0) {
    return GYRO_ERR_TEMP_READ;
  }

  // 7. Kisa delay (sensör boot için)
  gyro_ctx.mdelay(100);

  return GYRO_OK;
}

/**
  * @brief  Read gyroscope angular rate
  * @param  data  Pointer to 3x int16_t array [X, Y, Z]
  * @retval 0: OK, -1: Error
  */
static int32_t gyro_read(int16_t *data)
{
  return i3g4250d_angular_rate_raw_get(&gyro_ctx, data);
}

/**
  * @brief  Gyroscope self-test procedure
  * @retval 0: OK (sensor healthy), -1: FAIL (sensor faulty)
  */
static int32_t gyro_self_test(void)
{
  int16_t normal_data[3] = {0};
  int16_t selftest_data[3] = {0};
  int16_t diff_x, diff_y, diff_z;
  i3g4250d_st_t mode;
  char msg[100];

  i3g4250d_platform_print("\r\n--- SELF-TEST START ---\r\n");

  // 1. Read normal mode (self-test OFF)
  i3g4250d_self_test_set(&gyro_ctx, I3G4250D_GY_ST_DISABLE);

  // 2. Gerçekten aktif oldu mu kontrol et (SPI doğrulama)
  i3g4250d_self_test_get(&gyro_ctx, &mode);
  if (mode != I3G4250D_GY_ST_DISABLE) {
    i3g4250d_platform_print("ERROR: Self-test activation failed\r\n");
    return -1;
  }

  gyro_ctx.mdelay(100);

  gyro_read(normal_data);
  sprintf(msg, "Normal mode: X=%d Y=%d Z=%d\r\n",
          normal_data[0], normal_data[1], normal_data[2]);
  i3g4250d_platform_print(msg);

  // 2. Read self-test mode (positive actuation)
  i3g4250d_self_test_set(&gyro_ctx, I3G4250D_GY_ST_POSITIVE);

  // 2. Gerçekten aktif oldu mu kontrol et (SPI doğrulama)
  i3g4250d_self_test_get(&gyro_ctx, &mode);
  if (mode != I3G4250D_GY_ST_POSITIVE) {
    i3g4250d_platform_print("ERROR: Self-test activation failed\r\n");
    return -1;
  }

  gyro_ctx.mdelay(100);

  gyro_read(selftest_data);
  sprintf(msg, "Self-test mode: X=%d Y=%d Z=%d\r\n",
          selftest_data[0], selftest_data[1], selftest_data[2]);
  i3g4250d_platform_print(msg);

  // 3. Disable self-test
  i3g4250d_self_test_set(&gyro_ctx, I3G4250D_GY_ST_DISABLE);
  gyro_ctx.mdelay(50);

  // 4. Calculate absolute differences
  diff_x = selftest_data[0] - normal_data[0];
  diff_y = selftest_data[1] - normal_data[1];
  diff_z = selftest_data[2] - normal_data[2];

  if (diff_x < 0) diff_x = -diff_x;
  if (diff_y < 0) diff_y = -diff_y;
  if (diff_z < 0) diff_z = -diff_z;

  sprintf(msg, "Delta: X=%d Y=%d Z=%d\r\n", diff_x, diff_y, diff_z);
  i3g4250d_platform_print(msg);

  // 5. Validate against datasheet limits
  if ((diff_x < SELF_TEST_MIN_LSB || diff_x > SELF_TEST_MAX_LSB) ||
      (diff_y < SELF_TEST_MIN_LSB || diff_y > SELF_TEST_MAX_LSB) ||
      (diff_z < SELF_TEST_MIN_LSB || diff_z > SELF_TEST_MAX_LSB)) {
    i3g4250d_platform_print("SELF-TEST FAILED - Sensor faulty\r\n\r\n");
    return -1;
  }

  i3g4250d_platform_print("SELF-TEST PASSED - Sensor OK\r\n\r\n");
  return 0;
}

/**
  * @brief  Test different ODR (Output Data Rate) modes
  *         Demonstrates driver's configuration flexibility
  * @retval gyro_error_t
  */
static gyro_error_t gyro_test_odr_modes(void)
{
  char msg[100];
  i3g4250d_dr_t odr_read;
  int16_t test_data[3];
  uint8_t data_ready;

  const char* odr_names[] = {"100 Hz", "200 Hz", "400 Hz", "800 Hz"};
  const i3g4250d_dr_t odr_modes[] = {
    I3G4250D_ODR_100Hz,
    I3G4250D_ODR_200Hz,
    I3G4250D_ODR_400Hz,
    I3G4250D_ODR_800Hz
  };

  i3g4250d_platform_print("\r\n--- ODR TEST START ---\r\n");

  for (int i = 0; i < 4; i++) {
    // Set ODR
    if (i3g4250d_data_rate_set(&gyro_ctx, odr_modes[i]) != 0) {
      i3g4250d_platform_print("ERROR: ODR set failed\r\n");
      return GYRO_ERR_ODR_CONFIG;
    }

    // Verify ODR was set correctly (read-back)
    if (i3g4250d_data_rate_get(&gyro_ctx, &odr_read) != 0) {
      return GYRO_ERR_SPI_COMM;
    }

    if (odr_read != odr_modes[i]) {
      sprintf(msg, "ERROR: ODR verify failed (expected %d, got %d)\r\n",
              odr_modes[i], odr_read);
      i3g4250d_platform_print(msg);
      return GYRO_ERR_ODR_CONFIG;
    }

    // Wait for new data
    gyro_ctx.mdelay(50);

    // Wait for data ready
    i3g4250d_flag_data_ready_get(&gyro_ctx, &data_ready);
    if (!data_ready) {
      gyro_ctx.mdelay(20);  // Extra wait
    }

    // Read sample
    if (gyro_read(test_data) != 0) {
      return GYRO_ERR_DATA_READ;
    }

    sprintf(msg, "ODR %s: X=%d Y=%d Z=%d (verified)\r\n",
            odr_names[i], test_data[0], test_data[1], test_data[2]);
    i3g4250d_platform_print(msg);
  }

  // Restore default ODR (100 Hz)
  i3g4250d_data_rate_set(&gyro_ctx, I3G4250D_ODR_100Hz);

  i3g4250d_platform_print("ODR TEST PASSED\r\n\r\n");
  return GYRO_OK;
}

/**
  * @brief  Test different Full-Scale modes
  *         Shows driver's ability to handle different measurement ranges
  * @retval gyro_error_t
  */
static gyro_error_t gyro_test_fullscale_modes(void)
{
  char msg[120];
  i3g4250d_fs_t fs_read;
  int16_t test_data[3];
  uint8_t data_ready;

  // Sensitivity values (mdps/LSB) from datasheet
  const float sensitivities[] = {8.75f, 17.5f, 70.0f};
  const char* fs_names[] = {"245 dps", "500 dps", "2000 dps"};
  const i3g4250d_fs_t fs_modes[] = {
    I3G4250D_245dps,
    I3G4250D_500dps,
    I3G4250D_2000dps
  };

  i3g4250d_platform_print("\r\n--- FULL-SCALE TEST START ---\r\n");

  for (int i = 0; i < 3; i++) {
    // Set full-scale
    if (i3g4250d_full_scale_set(&gyro_ctx, fs_modes[i]) != 0) {
      i3g4250d_platform_print("ERROR: Full-scale set failed\r\n");
      return GYRO_ERR_FULLSCALE_CONFIG;
    }

    // Verify full-scale was set correctly (read-back)
    if (i3g4250d_full_scale_get(&gyro_ctx, &fs_read) != 0) {
      return GYRO_ERR_SPI_COMM;
    }

    if (fs_read != fs_modes[i]) {
      sprintf(msg, "ERROR: FS verify failed (expected %d, got %d)\r\n",
              fs_modes[i], fs_read);
      i3g4250d_platform_print(msg);
      return GYRO_ERR_FULLSCALE_CONFIG;
    }

    // Wait for new data
    gyro_ctx.mdelay(50);

    // Wait for data ready
    i3g4250d_flag_data_ready_get(&gyro_ctx, &data_ready);
    if (!data_ready) {
      gyro_ctx.mdelay(20);
    }

    // Read sample
    if (gyro_read(test_data) != 0) {
      return GYRO_ERR_DATA_READ;
    }

    // Calculate mdps using appropriate sensitivity
    int x_mdps = (int)(test_data[0] * sensitivities[i]);
    int y_mdps = (int)(test_data[1] * sensitivities[i]);
    int z_mdps = (int)(test_data[2] * sensitivities[i]);

    sprintf(msg, "FS +/-%s: Raw=[%d,%d,%d] -> [%d,%d,%d] mdps (sens=%.2f)\r\n",
            fs_names[i], test_data[0], test_data[1], test_data[2],
            x_mdps, y_mdps, z_mdps, sensitivities[i]);
    i3g4250d_platform_print(msg);
  }

  // Restore default full-scale (245 dps)
  i3g4250d_full_scale_set(&gyro_ctx, I3G4250D_245dps);

  i3g4250d_platform_print("FULL-SCALE TEST PASSED\r\n\r\n");
  return GYRO_OK;
}

/**
  * @brief  Dump all important registers for debugging
  *         Useful for production testing and troubleshooting
  */
static void gyro_debug_dump_registers(void)
{
  uint8_t reg_val;
  char msg[80];

  // Important registers to dump
  const uint8_t regs[] = {
    0x0F,  // WHO_AM_I
    0x20,  // CTRL_REG1
    0x21,  // CTRL_REG2
    0x22,  // CTRL_REG3
    0x23,  // CTRL_REG4
    0x24,  // CTRL_REG5
    0x27,  // STATUS_REG
    0x26,  // OUT_TEMP
  };

  const char* reg_names[] = {
    "WHO_AM_I  ",
    "CTRL_REG1 ",
    "CTRL_REG2 ",
    "CTRL_REG3 ",
    "CTRL_REG4 ",
    "CTRL_REG5 ",
    "STATUS_REG",
    "OUT_TEMP  ",
  };

  i3g4250d_platform_print("\r\n--- REGISTER DUMP ---\r\n");
  i3g4250d_platform_print("Addr  Name        Value    Binary\r\n");
  i3g4250d_platform_print("----  ----------  -----    --------\r\n");

  for (int i = 0; i < 8; i++) {
    i3g4250d_read_reg(&gyro_ctx, regs[i], &reg_val, 1);

    // Convert to binary string
    char binary[9];
    for (int b = 7; b >= 0; b--) {
      binary[7-b] = (reg_val & (1 << b)) ? '1' : '0';
    }
    binary[8] = '\0';

    sprintf(msg, "0x%02X  %s  0x%02X     %s\r\n",
            regs[i], reg_names[i], reg_val, binary);
    i3g4250d_platform_print(msg);
  }

  i3g4250d_platform_print("--- END DUMP ---\r\n\r\n");
}

/**
  * @brief  Convert error code to string for debugging
  * @param  err: Error code
  * @retval Pointer to error string
  */
static const char* gyro_error_to_string(gyro_error_t err)
{
  switch (err) {
    case GYRO_OK:                   return "OK";
    case GYRO_ERR_SPI_COMM:         return "SPI Communication Error";
    case GYRO_ERR_WRONG_DEVICE:     return "Wrong Device (WHO_AM_I mismatch)";
    case GYRO_ERR_POWER_MODE:       return "Power Mode Config Failed";
    case GYRO_ERR_AXIS_X_CONFIG:    return "X-Axis Config Failed";
    case GYRO_ERR_AXIS_Y_CONFIG:    return "Y-Axis Config Failed";
    case GYRO_ERR_AXIS_Z_CONFIG:    return "Z-Axis Config Failed";
    case GYRO_ERR_ODR_CONFIG:       return "ODR Config Failed";
    case GYRO_ERR_FULLSCALE_CONFIG: return "Full-Scale Config Failed";
    case GYRO_ERR_TEMP_READ:        return "Temperature Read Failed";
    case GYRO_ERR_SELFTEST_FAIL:    return "Self-Test Failed";
    case GYRO_ERR_DATA_READ:        return "Data Read Failed";
    case GYRO_ERR_TIMEOUT:          return "Operation Timeout";
    default:                        return "Unknown Error";
  }
}

/**
  * @brief  Test Power Mode (Normal/Power-Down)
  *         Gösterir: Güç yönetimi, sleep mode desteği
  * @retval gyro_error_t
  */
static gyro_error_t gyro_test_power_mode(void)
{
  char msg[80];
  uint8_t power_state;

  i3g4250d_platform_print("\r\n--- POWER MODE TEST ---\r\n");

  // 1. Power-down mode (güç tasarrufu)
  if (i3g4250d_power_mode_set(&gyro_ctx, PROPERTY_DISABLE) != 0) {
    return GYRO_ERR_POWER_MODE;
  }

  // Verify
  i3g4250d_power_mode_get(&gyro_ctx, &power_state);
  sprintf(msg, "Power-Down Mode: %s\r\n", power_state ? "FAIL" : "OK");
  i3g4250d_platform_print(msg);

  gyro_ctx.mdelay(50);

  // 2. Normal mode (aktif)
  if (i3g4250d_power_mode_set(&gyro_ctx, PROPERTY_ENABLE) != 0) {
    return GYRO_ERR_POWER_MODE;
  }

  // Verify
  i3g4250d_power_mode_get(&gyro_ctx, &power_state);
  sprintf(msg, "Normal Mode: %s\r\n", power_state ? "OK" : "FAIL");
  i3g4250d_platform_print(msg);

  i3g4250d_platform_print("POWER MODE TEST PASSED\r\n\r\n");
  return GYRO_OK;
}

/**
  * @brief  Test Axis Enable/Disable
  *         Gösterir: Eksen bazlı güç tasarrufu, seçici veri okuma
  * @retval gyro_error_t
  */
static gyro_error_t gyro_test_axis_enable(void)
{
  char msg[100];
  uint8_t x_en, y_en, z_en;
  int16_t test_data[3];

  i3g4250d_platform_print("\r\n--- AXIS ENABLE/DISABLE TEST ---\r\n");

  // 1. Sadece X ekseni aktif
  i3g4250d_axis_x_data_set(&gyro_ctx, PROPERTY_ENABLE);
  i3g4250d_axis_y_data_set(&gyro_ctx, PROPERTY_DISABLE);
  i3g4250d_axis_z_data_set(&gyro_ctx, PROPERTY_DISABLE);

  // Verify
  i3g4250d_axis_x_data_get(&gyro_ctx, &x_en);
  i3g4250d_axis_y_data_get(&gyro_ctx, &y_en);
  i3g4250d_axis_z_data_get(&gyro_ctx, &z_en);

  gyro_ctx.mdelay(50);
  gyro_read(test_data);

  sprintf(msg, "Only X enabled: X=%d, Y=%d, Z=%d (Y,Z should be ~0)\r\n",
          test_data[0], test_data[1], test_data[2]);
  i3g4250d_platform_print(msg);

  // 2. Sadece Y ekseni aktif
  i3g4250d_axis_x_data_set(&gyro_ctx, PROPERTY_DISABLE);
  i3g4250d_axis_y_data_set(&gyro_ctx, PROPERTY_ENABLE);
  i3g4250d_axis_z_data_set(&gyro_ctx, PROPERTY_DISABLE);

  gyro_ctx.mdelay(50);
  gyro_read(test_data);

  sprintf(msg, "Only Y enabled: X=%d, Y=%d, Z=%d (X,Z should be ~0)\r\n",
          test_data[0], test_data[1], test_data[2]);
  i3g4250d_platform_print(msg);

  // 3. Tüm eksenleri geri aç
  i3g4250d_axis_x_data_set(&gyro_ctx, PROPERTY_ENABLE);
  i3g4250d_axis_y_data_set(&gyro_ctx, PROPERTY_ENABLE);
  i3g4250d_axis_z_data_set(&gyro_ctx, PROPERTY_ENABLE);

  gyro_ctx.mdelay(50);
  gyro_read(test_data);

  sprintf(msg, "All axes enabled: X=%d, Y=%d, Z=%d\r\n",
          test_data[0], test_data[1], test_data[2]);
  i3g4250d_platform_print(msg);

  i3g4250d_platform_print("AXIS ENABLE TEST PASSED\r\n\r\n");
  return GYRO_OK;
}

/**
  * @brief  Test High-Pass Filter
  *         Gösterir: Sinyal işleme, DC offset kaldırma
  * @retval gyro_error_t
  */
static gyro_error_t gyro_test_high_pass_filter(void)
{
  char msg[100];
  i3g4250d_hpcf_t hp_cutoff;
  int16_t test_data[3];

  i3g4250d_platform_print("\r\n--- HIGH-PASS FILTER TEST ---\r\n");

  // Test farklı HP cutoff frekansları
  const i3g4250d_hpcf_t hp_levels[] = {
    I3G4250D_HP_LEVEL_0,  // En düşük cutoff
    I3G4250D_HP_LEVEL_5,  // Orta
    I3G4250D_HP_LEVEL_9   // En yüksek cutoff
  };
  const char* hp_names[] = {"Level 0 (lowest)", "Level 5 (mid)", "Level 9 (highest)"};

  for (int i = 0; i < 3; i++) {
    // HP bandwidth ayarla
    if (i3g4250d_hp_bandwidth_set(&gyro_ctx, hp_levels[i]) != 0) {
      return GYRO_ERR_SPI_COMM;
    }

    // Verify
    i3g4250d_hp_bandwidth_get(&gyro_ctx, &hp_cutoff);

    gyro_ctx.mdelay(50);
    gyro_read(test_data);

    sprintf(msg, "HP %s: X=%d Y=%d Z=%d\r\n",
            hp_names[i], test_data[0], test_data[1], test_data[2]);
    i3g4250d_platform_print(msg);
  }

  // HP Mode test (Normal, Reference, Autoreset)
  i3g4250d_platform_print("HP Mode: Normal\r\n");
  i3g4250d_hp_mode_set(&gyro_ctx, I3G4250D_HP_NORMAL_MODE_WITH_RST);

  // Restore default
  i3g4250d_hp_bandwidth_set(&gyro_ctx, I3G4250D_HP_LEVEL_0);

  i3g4250d_platform_print("HIGH-PASS FILTER TEST PASSED\r\n\r\n");
  return GYRO_OK;
}

/**
  * @brief  Test Low-Pass Bandwidth
  *         Gösterir: Anti-aliasing, gürültü azaltma
  * @retval gyro_error_t
  */
static gyro_error_t gyro_test_lp_bandwidth(void)
{
  char msg[100];
  i3g4250d_bw_t bw_read;
  int16_t test_data[3];

  const i3g4250d_bw_t bw_modes[] = {
    I3G4250D_CUT_OFF_LOW,
    I3G4250D_CUT_OFF_MEDIUM,
    I3G4250D_CUT_OFF_HIGH,
    I3G4250D_CUT_OFF_VERY_HIGH
  };
  const char* bw_names[] = {"LOW", "MEDIUM", "HIGH", "VERY_HIGH"};

  i3g4250d_platform_print("\r\n--- LOW-PASS BANDWIDTH TEST ---\r\n");

  for (int i = 0; i < 4; i++) {
    // Set bandwidth
    if (i3g4250d_lp_bandwidth_set(&gyro_ctx, bw_modes[i]) != 0) {
      return GYRO_ERR_SPI_COMM;
    }

    // Verify
    i3g4250d_lp_bandwidth_get(&gyro_ctx, &bw_read);

    gyro_ctx.mdelay(50);
    gyro_read(test_data);

    sprintf(msg, "LP BW %s: X=%d Y=%d Z=%d (verified: %s)\r\n",
            bw_names[i], test_data[0], test_data[1], test_data[2],
            (bw_read == bw_modes[i]) ? "OK" : "FAIL");
    i3g4250d_platform_print(msg);
  }

  // Restore default
  i3g4250d_lp_bandwidth_set(&gyro_ctx, I3G4250D_CUT_OFF_LOW);

  i3g4250d_platform_print("LOW-PASS BANDWIDTH TEST PASSED\r\n\r\n");
  return GYRO_OK;
}

/**
  * @brief  Test FIFO functionality
  *         Gösterir: Batch veri okuma, CPU yükü azaltma
  * @retval gyro_error_t
  */
static gyro_error_t gyro_test_fifo(void)
{
  char msg[100];
  uint8_t fifo_level, fifo_empty, fifo_ovr, fifo_wtm;
  i3g4250d_fifo_mode_t fifo_mode;

  i3g4250d_platform_print("\r\n--- FIFO TEST ---\r\n");

  // 1. FIFO Enable
  if (i3g4250d_fifo_enable_set(&gyro_ctx, PROPERTY_ENABLE) != 0) {
    return GYRO_ERR_SPI_COMM;
  }
  i3g4250d_platform_print("FIFO Enabled\r\n");

  // 2. Set FIFO mode to FIFO (normal FIFO mode)
  if (i3g4250d_fifo_mode_set(&gyro_ctx, I3G4250D_FIFO_MODE) != 0) {
    return GYRO_ERR_SPI_COMM;
  }

  // Verify mode
  i3g4250d_fifo_mode_get(&gyro_ctx, &fifo_mode);
  sprintf(msg, "FIFO Mode set to: %d (1=FIFO)\r\n", fifo_mode);
  i3g4250d_platform_print(msg);

  // 3. Set watermark (threshold)
  if (i3g4250d_fifo_watermark_set(&gyro_ctx, 10) != 0) {
    return GYRO_ERR_SPI_COMM;
  }
  i3g4250d_platform_print("FIFO Watermark set to 10\r\n");

  // 4. Wait for FIFO to fill
  gyro_ctx.mdelay(200);  // 100Hz ODR → 200ms ≈ 20 samples

  // 5. Check FIFO status
  i3g4250d_fifo_data_level_get(&gyro_ctx, &fifo_level);
  i3g4250d_fifo_empty_flag_get(&gyro_ctx, &fifo_empty);
  i3g4250d_fifo_ovr_flag_get(&gyro_ctx, &fifo_ovr);
  i3g4250d_fifo_wtm_flag_get(&gyro_ctx, &fifo_wtm);

  sprintf(msg, "FIFO Status: Level=%d, Empty=%d, Overrun=%d, Watermark=%d\r\n",
          fifo_level, fifo_empty, fifo_ovr, fifo_wtm);
  i3g4250d_platform_print(msg);

  // 6. Read FIFO samples
  int16_t fifo_data[3];
  int samples_read = 0;
  while (fifo_level > 0 && samples_read < 5) {  // Read up to 5 samples
    gyro_read(fifo_data);
    sprintf(msg, "FIFO[%d]: X=%d Y=%d Z=%d\r\n",
            samples_read, fifo_data[0], fifo_data[1], fifo_data[2]);
    i3g4250d_platform_print(msg);
    samples_read++;
    i3g4250d_fifo_data_level_get(&gyro_ctx, &fifo_level);
  }

  // 7. Set to Bypass mode (disable FIFO)
  i3g4250d_fifo_mode_set(&gyro_ctx, I3G4250D_FIFO_BYPASS_MODE);
  i3g4250d_fifo_enable_set(&gyro_ctx, PROPERTY_DISABLE);

  i3g4250d_platform_print("FIFO TEST PASSED\r\n\r\n");
  return GYRO_OK;
}

/**
  * @brief  Test Data Format (Big/Little Endian)
  *         Gösterir: Cross-platform uyumluluk
  * @retval gyro_error_t
  */
static gyro_error_t gyro_test_data_format(void)
{
  char msg[80];
  i3g4250d_ble_t ble_mode;

  i3g4250d_platform_print("\r\n--- DATA FORMAT TEST ---\r\n");

  // 1. Little Endian (LSB first - default)
  i3g4250d_data_format_set(&gyro_ctx, I3G4250D_AUX_LSB_AT_LOW_ADD);
  i3g4250d_data_format_get(&gyro_ctx, &ble_mode);
  sprintf(msg, "Little Endian: %s\r\n",
          (ble_mode == I3G4250D_AUX_LSB_AT_LOW_ADD) ? "OK" : "FAIL");
  i3g4250d_platform_print(msg);

  // 2. Big Endian (MSB first)
  i3g4250d_data_format_set(&gyro_ctx, I3G4250D_AUX_MSB_AT_LOW_ADD);
  i3g4250d_data_format_get(&gyro_ctx, &ble_mode);
  sprintf(msg, "Big Endian: %s\r\n",
          (ble_mode == I3G4250D_AUX_MSB_AT_LOW_ADD) ? "OK" : "FAIL");
  i3g4250d_platform_print(msg);

  // Restore default (Little Endian)
  i3g4250d_data_format_set(&gyro_ctx, I3G4250D_AUX_LSB_AT_LOW_ADD);

  i3g4250d_platform_print("DATA FORMAT TEST PASSED\r\n\r\n");
  return GYRO_OK;
}

/**
  * @brief  Test Boot/Reboot Memory
  *         Gösterir: Factory reset, register reload
  * @retval gyro_error_t
  */
static gyro_error_t gyro_test_boot(void)
{
  char msg[80];
  uint8_t boot_status;

  i3g4250d_platform_print("\r\n--- BOOT/REBOOT TEST ---\r\n");

  // Trigger boot (reload trimming parameters)
  i3g4250d_boot_set(&gyro_ctx, PROPERTY_ENABLE);

  // Check boot status
  i3g4250d_boot_get(&gyro_ctx, &boot_status);
  sprintf(msg, "Boot triggered, status: %d\r\n", boot_status);
  i3g4250d_platform_print(msg);

  // Wait for boot to complete
  gyro_ctx.mdelay(50);

  i3g4250d_boot_get(&gyro_ctx, &boot_status);
  sprintf(msg, "Boot complete, status: %d (should be 0)\r\n", boot_status);
  i3g4250d_platform_print(msg);

  i3g4250d_platform_print("BOOT TEST PASSED\r\n\r\n");
  return GYRO_OK;
}

/**
  * @brief  Test Temperature Sensor
  *         Gösterir: Ortam sıcaklığı izleme
  * @retval gyro_error_t
  */
static gyro_error_t gyro_test_temperature(void)
{
  char msg[80];
  uint8_t temp_raw_val;
  int temp_c;

  i3g4250d_platform_print("\r\n--- TEMPERATURE TEST ---\r\n");

  // Read multiple
  for (int i = 0; i < 3; i++) {
    if (i3g4250d_temperature_raw_get(&gyro_ctx, &temp_raw_val) != 0) {
      return GYRO_ERR_TEMP_READ;
    }

    temp_c = i3g4250d_from_lsb_to_celsius((int8_t)temp_raw_val);

    sprintf(msg, "Temp Sample %d: Raw=%d -> %d C\r\n",
            i+1, (int8_t)temp_raw_val, temp_c);
    i3g4250d_platform_print(msg);

    gyro_ctx.mdelay(100);
  }

  i3g4250d_platform_print("TEMPERATURE TEST PASSED\r\n\r\n");
  return GYRO_OK;
}

/**
  * @brief  Test SPI Mode (3-wire / 4-wire)
  *         Gösterir: Interface flexibility, farklı bağlantı seçenekleri
  * @retval gyro_error_t
  */
static gyro_error_t gyro_test_spi_mode(void)
{
  char msg[80];
  i3g4250d_sim_t spi_mode;

  i3g4250d_platform_print("\r\n--- SPI MODE TEST ---\r\n");

  // 1. Read current mode (should be 4-wire)
  i3g4250d_spi_mode_get(&gyro_ctx, &spi_mode);
  sprintf(msg, "Current SPI Mode: %s\r\n",
          (spi_mode == I3G4250D_SPI_4_WIRE) ? "4-wire" : "3-wire");
  i3g4250d_platform_print(msg);

  // NOT: 3-wire moduna geçiş yapmıyoruz çünkü donanım 4-wire bağlı
  // Sadece register okuma/yazma test ediyoruz

  // 2. Verify 4-wire mode is default
  if (spi_mode != I3G4250D_SPI_4_WIRE) {
    i3g4250d_platform_print("WARNING: SPI mode not 4-wire!\r\n");
  }

  i3g4250d_platform_print("SPI MODE TEST PASSED (4-wire verified)\r\n\r\n");
  return GYRO_OK;
}

/**
  * @brief  Test Filter Path Selection
  *         Gösterir: Output veri yolu konfigürasyonu (LPF1, LPF2, HP)
  * @retval gyro_error_t
  */
static gyro_error_t gyro_test_filter_path(void)
{
  char msg[100];
  i3g4250d_out_sel_t filter_path;
  int16_t test_data[3];

  const i3g4250d_out_sel_t paths[] = {
    I3G4250D_ONLY_LPF1_ON_OUT,           // 0: LPF1 only
    I3G4250D_LPF1_LPF2_ON_OUT,      // 1: LPF1 + LPF2
    I3G4250D_LPF1_HP_ON_OUT,        // 4: LPF1 + HP
    I3G4250D_LPF1_HP_LPF2_ON_OUT    // 5: LPF1 + LPF2 + HP
  };
  const char* path_names[] = {
    "LPF1 only",
    "LPF1+LPF2",
    "LPF1+HP",
    "LPF1+LPF2+HP"
  };

  i3g4250d_platform_print("\r\n--- FILTER PATH TEST ---\r\n");

  for (int i = 0; i < 4; i++) {
    // Set filter path
    if (i3g4250d_filter_path_set(&gyro_ctx, paths[i]) != 0) {
      return GYRO_ERR_SPI_COMM;
    }

    // Verify
    i3g4250d_filter_path_get(&gyro_ctx, &filter_path);

    gyro_ctx.mdelay(50);
    gyro_read(test_data);

    sprintf(msg, "Path %s: X=%d Y=%d Z=%d (%s)\r\n",
            path_names[i], test_data[0], test_data[1], test_data[2],
            (filter_path == paths[i]) ? "OK" : "FAIL");
    i3g4250d_platform_print(msg);
  }

  // Restore default
  i3g4250d_filter_path_set(&gyro_ctx, I3G4250D_ONLY_LPF1_ON_OUT);

  i3g4250d_platform_print("FILTER PATH TEST PASSED\r\n\r\n");
  return GYRO_OK;
}

/**
  * @brief  Test HP Reference Value
  *         Gösterir: High-pass filter referans değeri ayarı
  * @retval gyro_error_t
  */
static gyro_error_t gyro_test_hp_reference(void)
{
  char msg[80];
  uint8_t ref_val;

  i3g4250d_platform_print("\r\n--- HP REFERENCE TEST ---\r\n");

  // Test different reference values
  const uint8_t test_refs[] = {0x00, 0x40, 0x80, 0xFF};

  for (int i = 0; i < 4; i++) {
    // Set reference
    if (i3g4250d_hp_reference_value_set(&gyro_ctx, test_refs[i]) != 0) {
      return GYRO_ERR_SPI_COMM;
    }

    // Verify
    i3g4250d_hp_reference_value_get(&gyro_ctx, &ref_val);

    sprintf(msg, "HP Reference 0x%02X: %s\r\n",
            test_refs[i], (ref_val == test_refs[i]) ? "OK" : "FAIL");
    i3g4250d_platform_print(msg);
  }

  // Restore default
  i3g4250d_hp_reference_value_set(&gyro_ctx, 0x00);

  i3g4250d_platform_print("HP REFERENCE TEST PASSED\r\n\r\n");
  return GYRO_OK;
}

/**
  * @brief  Test Interrupt Pin Configuration
  *         Gösterir: INT1/INT2 pin routing, polarity, mode
  * @retval gyro_error_t
  */
static gyro_error_t gyro_test_interrupt_pins(void)
{
  char msg[100];
  i3g4250d_int1_route_t int1_route;
  i3g4250d_int2_route_t int2_route;
  i3g4250d_pp_od_t pin_mode;
  i3g4250d_h_lactive_t polarity;

  i3g4250d_platform_print("\r\n--- INTERRUPT PIN TEST ---\r\n");

  // 1. Test INT1 routing (interrupt enable on INT1)
  i3g4250d_pin_int1_route_set(&gyro_ctx, I3G4250D_INT1_ROUTE_INT1);
  i3g4250d_pin_int1_route_get(&gyro_ctx, &int1_route);
  sprintf(msg, "INT1 Route (INT1 enabled): %s\r\n",
          (int1_route & I3G4250D_INT1_ROUTE_INT1) ? "OK" : "FAIL");
  i3g4250d_platform_print(msg);

  // 2. Test INT2 routing (DRDY on INT2)
  i3g4250d_pin_int2_route_set(&gyro_ctx, I3G4250D_INT2_ROUTE_DRDY);
  i3g4250d_pin_int2_route_get(&gyro_ctx, &int2_route);
  sprintf(msg, "INT2 Route (DRDY enabled): %s\r\n",
          (int2_route & I3G4250D_INT2_ROUTE_DRDY) ? "OK" : "FAIL");
  i3g4250d_platform_print(msg);

  // 3. Test pin mode (Push-Pull vs Open-Drain)
  i3g4250d_pin_mode_set(&gyro_ctx, I3G4250D_PUSH_PULL);
  i3g4250d_pin_mode_get(&gyro_ctx, &pin_mode);
  sprintf(msg, "Pin Mode (Push-Pull): %s\r\n",
          (pin_mode == I3G4250D_PUSH_PULL) ? "OK" : "FAIL");
  i3g4250d_platform_print(msg);

  // 4. Test polarity (Active High vs Active Low)
  i3g4250d_pin_polarity_set(&gyro_ctx, I3G4250D_ACTIVE_HIGH);
  i3g4250d_pin_polarity_get(&gyro_ctx, &polarity);
  sprintf(msg, "Pin Polarity (Active High): %s\r\n",
          (polarity == I3G4250D_ACTIVE_HIGH) ? "OK" : "FAIL");
  i3g4250d_platform_print(msg);

  // Disable interrupts after test
  i3g4250d_pin_int1_route_set(&gyro_ctx, 0);
  i3g4250d_pin_int2_route_set(&gyro_ctx, 0);

  i3g4250d_platform_print("INTERRUPT PIN TEST PASSED\r\n\r\n");
  return GYRO_OK;
}

/**
  * @brief  Test Interrupt Notification Mode
  *         Gösterir: Latched vs Pulsed interrupt behavior
  * @retval gyro_error_t
  */
static gyro_error_t gyro_test_int_notification(void)
{
  char msg[80];
  i3g4250d_lir_t lir_mode;

  i3g4250d_platform_print("\r\n--- INT NOTIFICATION TEST ---\r\n");

  // 1. Test Latched mode
  i3g4250d_int_notification_set(&gyro_ctx, I3G4250D_INT_LATCHED);
  i3g4250d_int_notification_get(&gyro_ctx, &lir_mode);
  sprintf(msg, "Latched Mode: %s\r\n",
          (lir_mode == I3G4250D_INT_LATCHED) ? "OK" : "FAIL");
  i3g4250d_platform_print(msg);

  // 2. Test Pulsed mode
  i3g4250d_int_notification_set(&gyro_ctx, I3G4250D_INT_PULSED);
  i3g4250d_int_notification_get(&gyro_ctx, &lir_mode);
  sprintf(msg, "Pulsed Mode: %s\r\n",
          (lir_mode == I3G4250D_INT_PULSED) ? "OK" : "FAIL");
  i3g4250d_platform_print(msg);

  i3g4250d_platform_print("INT NOTIFICATION TEST PASSED\r\n\r\n");
  return GYRO_OK;
}

/**
  * @brief  Test Threshold Interrupt Configuration
  *         Gösterir: Eşik değeri tabanlı kesme oluşturma
  * @retval gyro_error_t
  */
static gyro_error_t gyro_test_threshold_interrupt(void)
{
  char msg[100];
  uint16_t thresh_x, thresh_y, thresh_z;
  i3g4250d_int1_src_t int_src;

  i3g4250d_platform_print("\r\n--- THRESHOLD INTERRUPT TEST ---\r\n");

  // 1. Set thresholds for each axis (15-bit value, max ~32767)
  uint16_t test_threshold = 1000;  // Test threshold value

  i3g4250d_int_x_threshold_set(&gyro_ctx, test_threshold);
  i3g4250d_int_y_threshold_set(&gyro_ctx, test_threshold);
  i3g4250d_int_z_threshold_set(&gyro_ctx, test_threshold);

  // 2. Verify thresholds
  i3g4250d_int_x_threshold_get(&gyro_ctx, &thresh_x);
  i3g4250d_int_y_threshold_get(&gyro_ctx, &thresh_y);
  i3g4250d_int_z_threshold_get(&gyro_ctx, &thresh_z);

  sprintf(msg, "Thresholds set: X=%d Y=%d Z=%d (expected %d)\r\n",
          thresh_x, thresh_y, thresh_z, test_threshold);
  i3g4250d_platform_print(msg);

  // 3. Read interrupt source register
  i3g4250d_int_on_threshold_src_get(&gyro_ctx, &int_src);
  sprintf(msg, "INT1_SRC Register: 0x%02X\r\n", *(uint8_t*)&int_src);
  i3g4250d_platform_print(msg);

  // 4. Test threshold mode (AND/OR combination)
  i3g4250d_int_on_threshold_mode_set(&gyro_ctx, I3G4250D_INT1_ON_TH_OR);
  i3g4250d_platform_print("Threshold Mode: OR\r\n");

  // 5. Test threshold duration
  i3g4250d_int_on_threshold_dur_set(&gyro_ctx, 10); // 10 samples
  i3g4250d_platform_print("Threshold Duration: 10 samples, WAIT enabled\r\n");

  // Clear thresholds after test
  i3g4250d_int_x_threshold_set(&gyro_ctx, 0);
  i3g4250d_int_y_threshold_set(&gyro_ctx, 0);
  i3g4250d_int_z_threshold_set(&gyro_ctx, 0);

  i3g4250d_platform_print("THRESHOLD INTERRUPT TEST PASSED\r\n\r\n");
  return GYRO_OK;
}

/**
  * @brief  Test Internal Filter Path (for interrupt generator)
  *         Gösterir: Interrupt generator için filter seçimi
  * @retval gyro_error_t
  */
static gyro_error_t gyro_test_filter_path_internal(void)
{
  char msg[100];
  i3g4250d_int1_sel_t int1_sel;

  const i3g4250d_int1_sel_t paths[] = {
    I3G4250D_ONLY_LPF1_ON_INT,
    I3G4250D_LPF1_LPF2_ON_INT,
    I3G4250D_LPF1_HP_ON_INT,
    I3G4250D_LPF1_HP_LPF2_ON_INT
  };
  const char* path_names[] = {
    "LPF1",
    "LPF1+LPF2",
    "LPF1+HP",
    "LPF1+LPF2+HP"
  };

  i3g4250d_platform_print("\r\n--- INTERNAL FILTER PATH TEST ---\r\n");

  for (int i = 0; i < 4; i++) {
    // Set internal filter path
    if (i3g4250d_filter_path_internal_set(&gyro_ctx, paths[i]) != 0) {
      return GYRO_ERR_SPI_COMM;
    }

    // Verify
    i3g4250d_filter_path_internal_get(&gyro_ctx, &int1_sel);

    sprintf(msg, "INT1 Filter %s: %s\r\n",
            path_names[i], (int1_sel == paths[i]) ? "OK" : "FAIL");
    i3g4250d_platform_print(msg);
  }

  // Restore default
  i3g4250d_filter_path_internal_set(&gyro_ctx, I3G4250D_ONLY_LPF1_ON_INT);

  i3g4250d_platform_print("INTERNAL FILTER PATH TEST PASSED\r\n\r\n");
  return GYRO_OK;
}

/**
  * =============================================================================
  * @brief  TÜM İŞLEVSELLİK TESTİ (Comprehensive Driver Test Suite)
  * =============================================================================
  *         Bu fonksiyon tüm driver özelliklerini test eder.
  *         Sunumda "driver'ın tüm işlevselliği" sorusuna cevap verir.
  *
  * @retval gyro_error_t - GYRO_OK ise tüm testler başarılı
  */
static gyro_error_t gyro_run_all_tests(void)
{
  gyro_error_t result;
  int passed = 0;
  int failed = 0;

  i3g4250d_platform_print("\r\n");
  i3g4250d_platform_print("╔═══════════════════════════════════════════════════════════╗\r\n");
  i3g4250d_platform_print("║       I3G4250D DRIVER - FULL FUNCTIONALITY TEST           ║\r\n");
  i3g4250d_platform_print("╚═══════════════════════════════════════════════════════════╝\r\n\r\n");

  // ═══════════════════════════════════════════════════════════════════════════
  // TEST 1: Register Dump (Debug bilgisi)
  // ═══════════════════════════════════════════════════════════════════════════
  gyro_debug_dump_registers();
  passed++;

  // ═══════════════════════════════════════════════════════════════════════════
  // TEST 2: Self-Test (Sensör sağlık kontrolü)
  // Neden önemli: Sensörün fiziksel olarak düzgün çalıştığını doğrular
  // ═══════════════════════════════════════════════════════════════════════════
  if (gyro_self_test() == 0) {
    passed++;
  } else {
    failed++;
    i3g4250d_platform_print("!!! SELF-TEST FAILED !!!\r\n");
  }

  // ═══════════════════════════════════════════════════════════════════════════
  // TEST 3: ODR Değişimi (100/200/400/800 Hz)
  // Neden önemli: Driver'ın farklı veri hızlarını desteklediğini gösterir
  // ═══════════════════════════════════════════════════════════════════════════
  result = gyro_test_odr_modes();
  if (result == GYRO_OK) { passed++; } else { failed++; }

  // ═══════════════════════════════════════════════════════════════════════════
  // TEST 4: Full-Scale Değişimi (±245/±500/±2000 dps)
  // Neden önemli: Farklı ölçüm aralıklarını ve sensitivity'yi gösterir
  // ═══════════════════════════════════════════════════════════════════════════
  result = gyro_test_fullscale_modes();
  if (result == GYRO_OK) { passed++; } else { failed++; }

  // ═══════════════════════════════════════════════════════════════════════════
  // TEST 5: Power Mode (Normal/Power-Down)
  // Neden önemli: Güç yönetimi, bataryalı cihazlar için kritik
  // ═══════════════════════════════════════════════════════════════════════════
  result = gyro_test_power_mode();
  if (result == GYRO_OK) { passed++; } else { failed++; }

  // ═══════════════════════════════════════════════════════════════════════════
  // TEST 6: Axis Enable/Disable (X/Y/Z ayrı ayrı)
  // Neden önemli: Seçici veri okuma, güç tasarrufu
  // ═══════════════════════════════════════════════════════════════════════════
  result = gyro_test_axis_enable();
  if (result == GYRO_OK) { passed++; } else { failed++; }

  // ═══════════════════════════════════════════════════════════════════════════
  // TEST 7: High-Pass Filter
  // Neden önemli: DC offset kaldırma, sinyal işleme
  // ═══════════════════════════════════════════════════════════════════════════
  result = gyro_test_high_pass_filter();
  if (result == GYRO_OK) { passed++; } else { failed++; }

  // ═══════════════════════════════════════════════════════════════════════════
  // TEST 8: Low-Pass Bandwidth
  // Neden önemli: Anti-aliasing, gürültü filtreleme
  // ═══════════════════════════════════════════════════════════════════════════
  result = gyro_test_lp_bandwidth();
  if (result == GYRO_OK) { passed++; } else { failed++; }

  // ═══════════════════════════════════════════════════════════════════════════
  // TEST 9: FIFO
  // Neden önemli: Batch veri okuma, CPU yükü azaltma, buffer yönetimi
  // ═══════════════════════════════════════════════════════════════════════════
  result = gyro_test_fifo();
  if (result == GYRO_OK) { passed++; } else { failed++; }

  // ═══════════════════════════════════════════════════════════════════════════
  // TEST 10: Data Format (Big/Little Endian)
  // Neden önemli: Cross-platform uyumluluk
  // ═══════════════════════════════════════════════════════════════════════════
  result = gyro_test_data_format();
  if (result == GYRO_OK) { passed++; } else { failed++; }

  // ═══════════════════════════════════════════════════════════════════════════
  // TEST 11: Boot/Reboot
  // Neden önemli: Factory reset, hata kurtarma
  // ═══════════════════════════════════════════════════════════════════════════
  result = gyro_test_boot();
  if (result == GYRO_OK) { passed++; } else { failed++; }

  // ═══════════════════════════════════════════════════════════════════════════
  // TEST 12: Temperature Sensor
  // Neden önemli: Termal izleme, sıcaklık kompanzasyonu
  // ═══════════════════════════════════════════════════════════════════════════
  result = gyro_test_temperature();
  if (result == GYRO_OK) { passed++; } else { failed++; }

  // ═══════════════════════════════════════════════════════════════════════════
  // TEST 13: SPI Mode (3-wire/4-wire)
  // Neden önemli: Interface esnekliği, farklı donanım konfigürasyonları
  // ═══════════════════════════════════════════════════════════════════════════
  result = gyro_test_spi_mode();
  if (result == GYRO_OK) { passed++; } else { failed++; }

  // ═══════════════════════════════════════════════════════════════════════════
  // TEST 14: Filter Path Selection
  // Neden önemli: Sinyal işleme yolu, data kalitesi optimizasyonu
  // ═══════════════════════════════════════════════════════════════════════════
  result = gyro_test_filter_path();
  if (result == GYRO_OK) { passed++; } else { failed++; }

  // ═══════════════════════════════════════════════════════════════════════════
  // TEST 15: HP Reference Value
  // Neden önemli: HP filter referans ayarı, offset kalibrasyonu
  // ═══════════════════════════════════════════════════════════════════════════
  result = gyro_test_hp_reference();
  if (result == GYRO_OK) { passed++; } else { failed++; }

  // ═══════════════════════════════════════════════════════════════════════════
  // TEST 16: Interrupt Pin Configuration
  // Neden önemli: Hardware interrupt routing, event-driven tasarım
  // ═══════════════════════════════════════════════════════════════════════════
  result = gyro_test_interrupt_pins();
  if (result == GYRO_OK) { passed++; } else { failed++; }

  // ═══════════════════════════════════════════════════════════════════════════
  // TEST 17: Interrupt Notification Mode
  // Neden önemli: Latched vs Pulsed, interrupt davranış kontrolü
  // ═══════════════════════════════════════════════════════════════════════════
  result = gyro_test_int_notification();
  if (result == GYRO_OK) { passed++; } else { failed++; }

  // ═══════════════════════════════════════════════════════════════════════════
  // TEST 18: Threshold Interrupt Configuration
  // Neden önemli: Motion detection, wake-on-motion, güç tasarrufu
  // ═══════════════════════════════════════════════════════════════════════════
  result = gyro_test_threshold_interrupt();
  if (result == GYRO_OK) { passed++; } else { failed++; }

  // ═══════════════════════════════════════════════════════════════════════════
  // TEST 19: Internal Filter Path (INT1)
  // Neden önemli: Interrupt generator sinyal işleme yolu
  // ═══════════════════════════════════════════════════════════════════════════
  result = gyro_test_filter_path_internal();
  if (result == GYRO_OK) { passed++; } else { failed++; }

  // ═══════════════════════════════════════════════════════════════════════════
  // SONUÇ RAPORU
  // ═══════════════════════════════════════════════════════════════════════════
  char summary[120];
  i3g4250d_platform_print("\r\n");
  i3g4250d_platform_print("╔═══════════════════════════════════════════════════════════╗\r\n");
  i3g4250d_platform_print("║                    TEST SONUCLARI                         ║\r\n");
  i3g4250d_platform_print("╚═══════════════════════════════════════════════════════════╝\r\n");

  sprintf(summary, "Gecen: %d  |  Kalan: %d  |  Toplam: 19\r\n",
          passed, failed);
  i3g4250d_platform_print(summary);

  if (failed == 0) {
    i3g4250d_platform_print("\r\n*** TUM TESTLER BASARILI - DRIVER FULLY FUNCTIONAL ***\r\n\r\n");
    return GYRO_OK;
  } else {
    i3g4250d_platform_print("\r\n!!! BAZI TESTLER BASARISIZ !!!\r\n\r\n");
    return GYRO_ERR_SELFTEST_FAIL;
  }
}

/* USER CODE END 0 */

int main(void)
{

  /* MCU Configuration--------------------------------------------------------*/

  /* Reset of all peripherals, Initializes the Flash interface and the Systick. */
  HAL_Init();

  /* Configure the system clock */
  SystemClock_Config();

  /* Initialize all configured peripherals */
  MX_GPIO_Init();
  MX_CRC_Init();
  MX_DMA2D_Init();
  MX_FMC_Init();
  MX_I2C3_Init();
  MX_LTDC_Init();
  MX_SPI5_Init();
  MX_TIM1_Init();
  MX_USART1_UART_Init();
  /* USER CODE BEGIN 2 */

  // Platform layer'i başlat
  i3g4250d_platform_init(&gyro_ctx, &hspi5);

  // Gyroscope başlat
  gyro_error_t status = gyro_init();

  if (status == GYRO_OK) {

    i3g4250d_platform_led_on(0);  // Green LED

    // ═══════════════════════════════════════════════════════════════════════
    // TÜM İŞLEVSELLİK TESTİ - Yorumu kaldırarak aktif et!
    // Tüm driver özelliklerini tek seferde test eder (Sunumda kullan)
    // ═══════════════════════════════════════════════════════════════════════
     gyro_run_all_tests();  // <-- YORUMU KALDIR: Tüm testleri çalıştırır

    i3g4250d_platform_print("\r\n=== GYROSCOPE INITIALIZED ===\r\n");

    char msg[100];
    sprintf(msg, "WHO_AM_I: 0x%02X (OK)\r\n\r\n", whoami_id);
    i3g4250d_platform_print(msg);

    while(1) {
      uint8_t data_ready = 0;

      // Veri hazir mi kontrol et
      i3g4250d_flag_data_ready_get(&gyro_ctx, &data_ready);

      if (data_ready) {
        // Yeni veri hazir, oku!
        gyro_read(gyro_data);

        // mdps'ye çevir
        int x_mdps = i3g4250d_from_fs245dps_to_mdps(gyro_data[0]);
        int y_mdps = i3g4250d_from_fs245dps_to_mdps(gyro_data[1]);
        int z_mdps = i3g4250d_from_fs245dps_to_mdps(gyro_data[2]);

        // Sicaklik oku
        i3g4250d_temperature_raw_get(&gyro_ctx, &temp_raw);
        temp_celsius = i3g4250d_from_lsb_to_celsius((int8_t)temp_raw);
        int temp_int = (int)temp_celsius;

        // UART'a gönder
        sprintf(msg, "X:%d Y:%d Z:%d MDPS TEMP:%d\r\n",
                x_mdps, y_mdps, z_mdps, temp_int);
        i3g4250d_platform_print(msg);

      }

      i3g4250d_platform_delay(100);  // Kisa delay (CPU'yu meşgul etme)
    }
  } else {  // Error handling with descriptive message
    char err_msg[100];
    sprintf(err_msg, "\r\nERROR: %s (code: %d)\r\n",
            gyro_error_to_string(status), status);
    i3g4250d_platform_print(err_msg);

    i3g4250d_platform_led_on(PROPERTY_ENABLE);  // Red LED
    while(1);
  }

  /* USER CODE END 2 */

  /* Call init function for freertos objects (in cmsis_os2.c) */
  MX_FREERTOS_Init();

  /* Start scheduler */
  osKernelStart();

  /* We should never get here as control is now taken by the scheduler */

  /* Infinite loop */
  while (1)
  {

  }
}

void SystemClock_Config(void)
{
  RCC_OscInitTypeDef RCC_OscInitStruct = {0};
  RCC_ClkInitTypeDef RCC_ClkInitStruct = {0};

  /** Configure the main internal regulator output voltage
  */
  __HAL_RCC_PWR_CLK_ENABLE();
  __HAL_PWR_VOLTAGESCALING_CONFIG(PWR_REGULATOR_VOLTAGE_SCALE3);

  /** Initializes the RCC Oscillators according to the specified parameters
  * in the RCC_OscInitTypeDef structure.
  */
  RCC_OscInitStruct.OscillatorType = RCC_OSCILLATORTYPE_HSE;
  RCC_OscInitStruct.HSEState = RCC_HSE_ON;
  RCC_OscInitStruct.PLL.PLLState = RCC_PLL_ON;
  RCC_OscInitStruct.PLL.PLLSource = RCC_PLLSOURCE_HSE;
  RCC_OscInitStruct.PLL.PLLM = 4;
  RCC_OscInitStruct.PLL.PLLN = 72;
  RCC_OscInitStruct.PLL.PLLP = RCC_PLLP_DIV2;
  RCC_OscInitStruct.PLL.PLLQ = 3;
  if (HAL_RCC_OscConfig(&RCC_OscInitStruct) != HAL_OK)
  {
    Error_Handler();
  }

  /** Initializes the CPU, AHB and APB buses clocks
  */
  RCC_ClkInitStruct.ClockType = RCC_CLOCKTYPE_HCLK|RCC_CLOCKTYPE_SYSCLK
                              |RCC_CLOCKTYPE_PCLK1|RCC_CLOCKTYPE_PCLK2;
  RCC_ClkInitStruct.SYSCLKSource = RCC_SYSCLKSOURCE_PLLCLK;
  RCC_ClkInitStruct.AHBCLKDivider = RCC_SYSCLK_DIV1;
  RCC_ClkInitStruct.APB1CLKDivider = RCC_HCLK_DIV2;
  RCC_ClkInitStruct.APB2CLKDivider = RCC_HCLK_DIV1;

  if (HAL_RCC_ClockConfig(&RCC_ClkInitStruct, FLASH_LATENCY_2) != HAL_OK)
  {
    Error_Handler();
  }
}

void HAL_TIM_PeriodElapsedCallback(TIM_HandleTypeDef *htim)
{
  if (htim->Instance == TIM6)
  {
    HAL_IncTick();
  }
}

void Error_Handler(void)
{
  __disable_irq();
  while (1)
  {
  }
}

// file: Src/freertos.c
/* USER CODE BEGIN Header */
/**
  ******************************************************************************
  * File Name          : freertos.c
  * Description        : Code for freertos applications
  ******************************************************************************
  * @attention
  *
  * Copyright (c) 2026 STMicroelectronics.
  * All rights reserved.
  *
  * This software is licensed under terms that can be found in the LICENSE file
  * in the root directory of this software component.
  * If no LICENSE file comes with this software, it is provided AS-IS.
  *
  ******************************************************************************
  */
/* USER CODE END Header */

#include "FreeRTOS.h"
#include "task.h"
#include "main.h"
#include "cmsis_os.h"

osThreadId defaultTaskHandle;

void StartDefaultTask(void const * argument);

extern void MX_USB_HOST_Init(void);
void MX_FREERTOS_Init(void); /* (MISRA C 2004 rule 8.1) */

/* GetIdleTaskMemory prototype (linked to static allocation support) */
void vApplicationGetIdleTaskMemory( StaticTask_t **ppxIdleTaskTCBBuffer, StackType_t **ppxIdleTaskStackBuffer, uint32_t *pulIdleTaskStackSize );

/* Hook prototypes */
void vApplicationIdleHook(void);
void vApplicationStackOverflowHook(xTaskHandle xTask, signed char *pcTaskName);
void vApplicationMallocFailedHook(void);

/* USER CODE BEGIN 2 */
__weak void vApplicationIdleHook( void )
{
   /* vApplicationIdleHook() will only be called if configUSE_IDLE_HOOK is set
   to 1 in FreeRTOSConfig.h. It will be called on each iteration of the idle
   task. It is essential that code added to this hook function never attempts
   to block in any way (for example, call xQueueReceive() with a block time
   specified, or call vTaskDelay()). If the application makes use of the
   vTaskDelete() API function (as this demo application does) then it is also
   important that vApplicationIdleHook() is permitted to return to its calling
   function, because it is the responsibility of the idle task to clean up
   memory allocated by the kernel to any task that has since been deleted. */
}
/* USER CODE END 2 */

/* USER CODE BEGIN 4 */
__weak void vApplicationStackOverflowHook(xTaskHandle xTask, signed char *pcTaskName)
{
   /* Run time stack overflow checking is performed if
   configCHECK_FOR_STACK_OVERFLOW is defined to 1 or 2. This hook function is
   called if a stack overflow is detected. */
}
/* USER CODE END 4 */

/* USER CODE BEGIN 5 */
__weak void vApplicationMallocFailedHook(void)
{
   /* vApplicationMallocFailedHook() will only be called if
   configUSE_MALLOC_FAILED_HOOK is set to 1 in FreeRTOSConfig.h. It is a hook
   function that will get called if a call to pvPortMalloc() fails.
   pvPortMalloc() is called internally by the kernel whenever a task, queue,
   timer or semaphore is created. It is also called by various parts of the
   demo application. If heap_1.c or heap_2.c are used, then the size of the
   heap available to pvPortMalloc() is defined by configTOTAL_HEAP_SIZE in
   FreeRTOSConfig.h, and the xPortGetFreeHeapSize() API function can be used
   to query the size of free heap space that remains (although it does not
   provide information on how the remaining heap might be fragmented). */
}
/* USER CODE END 5 */

/* USER CODE BEGIN GET_IDLE_TASK_MEMORY */
static StaticTask_t xIdleTaskTCBBuffer;
static StackType_t xIdleStack[configMINIMAL_STACK_SIZE];

void vApplicationGetIdleTaskMemory( StaticTask_t **ppxIdleTaskTCBBuffer, StackType_t **ppxIdleTaskStackBuffer, uint32_t *pulIdleTaskStackSize )
{
  *ppxIdleTaskTCBBuffer = &xIdleTaskTCBBuffer;
  *ppxIdleTaskStackBuffer = &xIdleStack[0];
  *pulIdleTaskStackSize = configMINIMAL_STACK_SIZE;
  /* place for user code */
}
/* USER CODE END GET_IDLE_TASK_MEMORY */

void MX_FREERTOS_Init(void) {

  /* Create the thread(s) */
  /* definition and creation of defaultTask */
  osThreadDef(defaultTask, StartDefaultTask, osPriorityNormal, 0, 4096);
  defaultTaskHandle = osThreadCreate(osThread(defaultTask), NULL);

}

void StartDefaultTask(void const * argument)
{
  /* init code for USB_HOST */
  MX_USB_HOST_Init();
  for(;;)
  {
    osDelay(1);
  }
}
